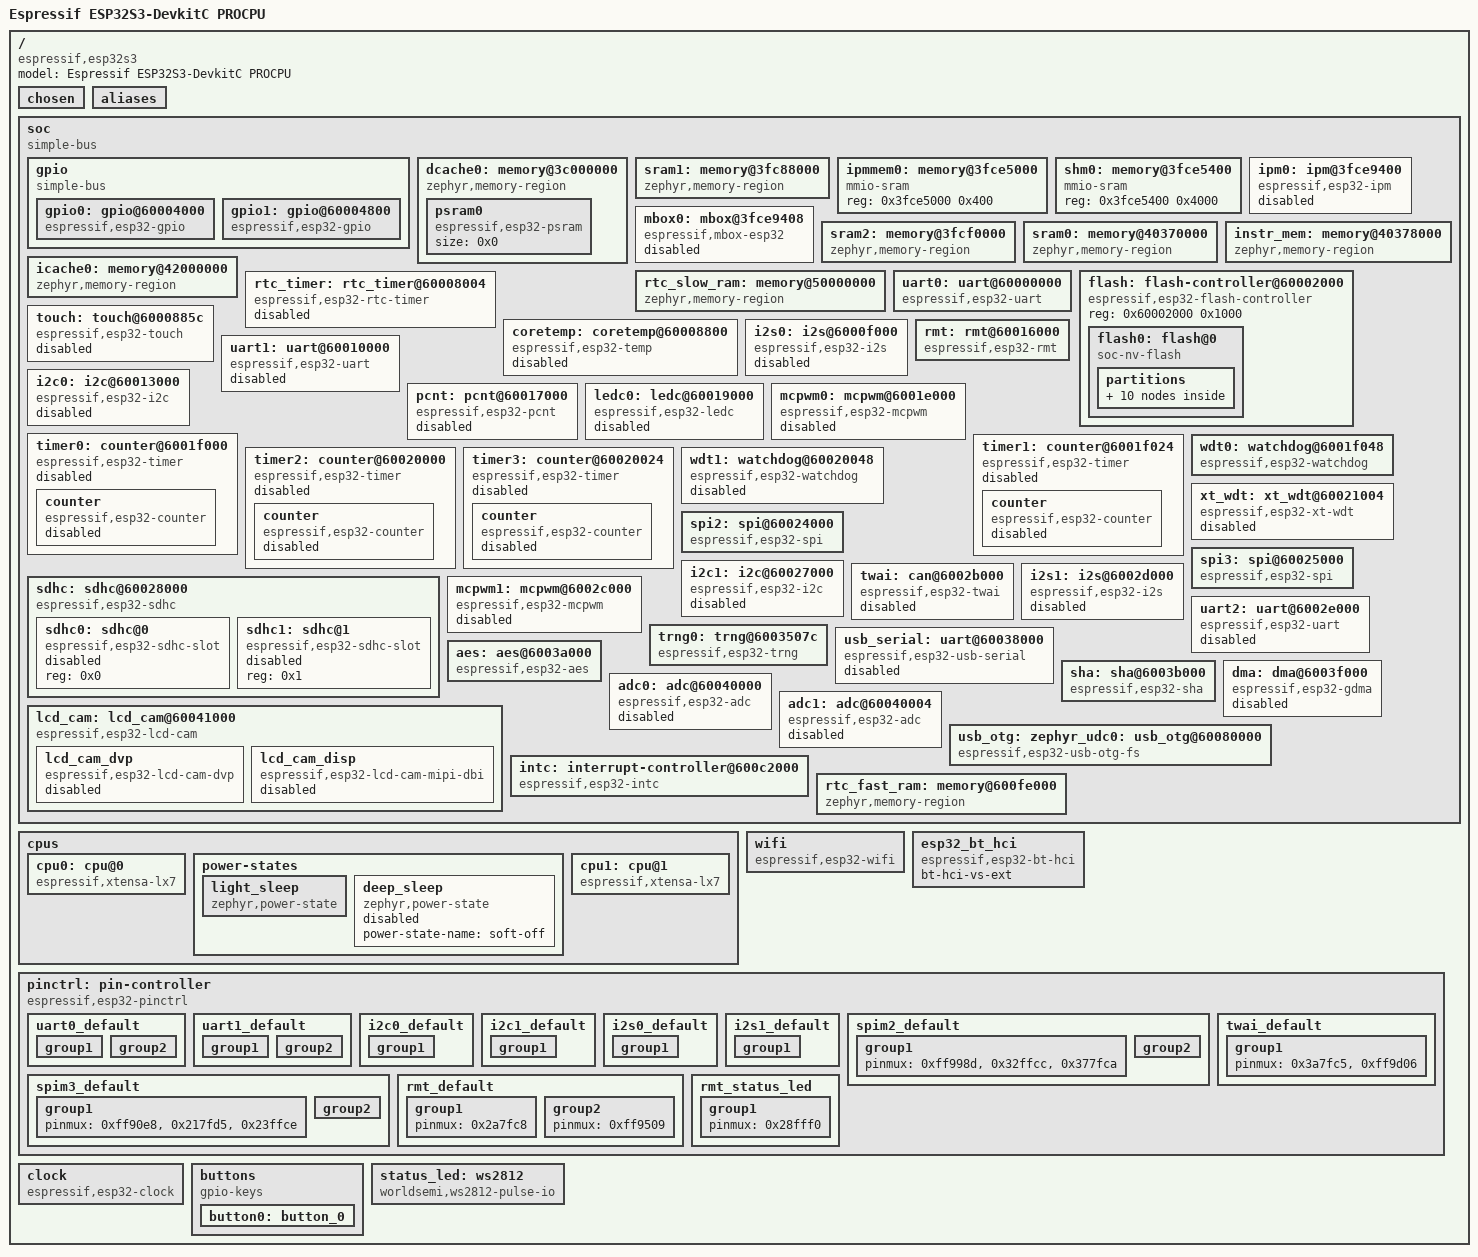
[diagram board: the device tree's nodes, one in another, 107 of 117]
/dts-v1/;

/* node '/' defined in zephyr/dts/common/skeleton.dtsi:9 */
/ {
	#address-cells = < 0x1 >;                   /* in zephyr/dts/common/skeleton.dtsi:10 */
	#size-cells = < 0x1 >;                      /* in zephyr/dts/common/skeleton.dtsi:11 */
	compatible = "espressif,esp32s3";           /* in zephyr/boards/espressif/esp32s3_devkitc/esp32s3_devkitc_procpu.dts:15 */
	model = "Espressif ESP32S3-DevkitC PROCPU"; /* in zephyr/boards/espressif/esp32s3_devkitc/esp32s3_devkitc_procpu.dts:16 */

	/* node '/chosen' defined in zephyr/dts/common/skeleton.dtsi:13 */
	chosen {
		zephyr,canbus = &twai;                    /* in zephyr/dts/xtensa/espressif/esp32s3/esp32s3_common.dtsi:22 */
		zephyr,entropy = &trng0;                  /* in zephyr/dts/xtensa/espressif/esp32s3/esp32s3_common.dtsi:23 */
		zephyr,flash-controller = &flash;         /* in zephyr/dts/xtensa/espressif/esp32s3/esp32s3_common.dtsi:24 */
		zephyr,sram = &sram1;                     /* in zephyr/boards/espressif/esp32s3_devkitc/esp32s3_devkitc_procpu.dts:26 */
		zephyr,console = &uart0;                  /* in zephyr/boards/espressif/esp32s3_devkitc/esp32s3_devkitc_procpu.dts:27 */
		zephyr,shell-uart = &uart0;               /* in zephyr/boards/espressif/esp32s3_devkitc/esp32s3_devkitc_procpu.dts:28 */
		zephyr,flash = &flash0;                   /* in zephyr/boards/espressif/esp32s3_devkitc/esp32s3_devkitc_procpu.dts:29 */
		zephyr,code-partition = &slot0_partition; /* in zephyr/boards/espressif/esp32s3_devkitc/esp32s3_devkitc_procpu.dts:30 */
		zephyr,bt-hci = &esp32_bt_hci;            /* in zephyr/boards/espressif/esp32s3_devkitc/esp32s3_devkitc_procpu.dts:31 */
	};

	/* node '/aliases' defined in zephyr/dts/common/skeleton.dtsi:15 */
	aliases {
		die-temp0 = &coretemp; /* in zephyr/dts/xtensa/espressif/esp32s3/esp32s3_common.dtsi:18 */
		i2c-0 = &i2c0;         /* in zephyr/boards/espressif/esp32s3_devkitc/esp32s3_devkitc_procpu.dts:19 */
		watchdog0 = &wdt0;     /* in zephyr/boards/espressif/esp32s3_devkitc/esp32s3_devkitc_procpu.dts:20 */
		uart-0 = &uart0;       /* in zephyr/boards/espressif/esp32s3_devkitc/esp32s3_devkitc_procpu.dts:21 */
		sw0 = &button0;        /* in zephyr/boards/espressif/esp32s3_devkitc/esp32s3_devkitc_procpu.dts:22 */
	};

	/* node '/soc' defined in zephyr/dts/xtensa/xtensa.dtsi:10 */
	soc {
		compatible = "simple-bus"; /* in zephyr/dts/xtensa/espressif/esp32s3/esp32s3_common.dtsi:97 */
		ranges;                    /* in zephyr/dts/xtensa/espressif/esp32s3/esp32s3_common.dtsi:98 */
		#address-cells = < 0x1 >;  /* in zephyr/dts/xtensa/espressif/esp32s3/esp32s3_common.dtsi:99 */
		#size-cells = < 0x1 >;     /* in zephyr/dts/xtensa/espressif/esp32s3/esp32s3_common.dtsi:100 */

		/* node '/soc/gpio' defined in zephyr/dts/xtensa/espressif/esp32s3/esp32s3_common.dtsi:102 */
		gpio: gpio {
			compatible = "simple-bus";                                     /* in zephyr/dts/xtensa/espressif/esp32s3/esp32s3_common.dtsi:103 */
			ranges;                                                        /* in zephyr/dts/xtensa/espressif/esp32s3/esp32s3_common.dtsi:104 */
			gpio-map-mask = < 0xffffffe0 0xffffffc0 >;                     /* in zephyr/dts/xtensa/espressif/esp32s3/esp32s3_common.dtsi:105 */
			gpio-map-pass-thru = < 0x1f 0x3f >;                            /* in zephyr/dts/xtensa/espressif/esp32s3/esp32s3_common.dtsi:106 */
			gpio-map = < 0x0 0x0 &gpio0 0x0 0x0 0x20 0x0 &gpio1 0x0 0x0 >; /* in zephyr/dts/xtensa/espressif/esp32s3/esp32s3_common.dtsi:107 */
			#gpio-cells = < 0x2 >;                                         /* in zephyr/dts/xtensa/espressif/esp32s3/esp32s3_common.dtsi:109 */
			#address-cells = < 0x1 >;                                      /* in zephyr/dts/xtensa/espressif/esp32s3/esp32s3_common.dtsi:110 */
			#size-cells = < 0x1 >;                                         /* in zephyr/dts/xtensa/espressif/esp32s3/esp32s3_common.dtsi:111 */

			/* node '/soc/gpio/gpio@60004000' defined in zephyr/dts/xtensa/espressif/esp32s3/esp32s3_common.dtsi:113 */
			gpio0: gpio@60004000 {
				compatible = "espressif,esp32-gpio"; /* in zephyr/dts/xtensa/espressif/esp32s3/esp32s3_common.dtsi:114 */
				reg = < 0x60004000 0x800 >;          /* in zephyr/dts/xtensa/espressif/esp32s3/esp32s3_common.dtsi:115 */
				gpio-controller;                     /* in zephyr/dts/xtensa/espressif/esp32s3/esp32s3_common.dtsi:116 */
				#gpio-cells = < 0x2 >;               /* in zephyr/dts/xtensa/espressif/esp32s3/esp32s3_common.dtsi:117 */
				interrupts = < 0x10 0x0 0x0 >;       /* in zephyr/dts/xtensa/espressif/esp32s3/esp32s3_common.dtsi:118 */
				interrupt-parent = < &intc >;        /* in zephyr/dts/xtensa/espressif/esp32s3/esp32s3_common.dtsi:119 */
				ngpios = < 0x20 >;                   /* in zephyr/dts/xtensa/espressif/esp32s3/esp32s3_common.dtsi:125 */
				status = "okay";                     /* in zephyr/boards/espressif/esp32s3_devkitc/esp32s3_devkitc_procpu.dts:62 */
				phandle = < 0x1 >;                   /* in zephyr/dts/xtensa/espressif/esp32s3/esp32s3_common.dtsi:107 */
			};

			/* node '/soc/gpio/gpio@60004800' defined in zephyr/dts/xtensa/espressif/esp32s3/esp32s3_common.dtsi:128 */
			gpio1: gpio@60004800 {
				compatible = "espressif,esp32-gpio"; /* in zephyr/dts/xtensa/espressif/esp32s3/esp32s3_common.dtsi:129 */
				reg = < 0x60004800 0x800 >;          /* in zephyr/dts/xtensa/espressif/esp32s3/esp32s3_common.dtsi:130 */
				gpio-controller;                     /* in zephyr/dts/xtensa/espressif/esp32s3/esp32s3_common.dtsi:131 */
				#gpio-cells = < 0x2 >;               /* in zephyr/dts/xtensa/espressif/esp32s3/esp32s3_common.dtsi:132 */
				interrupts = < 0x10 0x0 0x0 >;       /* in zephyr/dts/xtensa/espressif/esp32s3/esp32s3_common.dtsi:133 */
				interrupt-parent = < &intc >;        /* in zephyr/dts/xtensa/espressif/esp32s3/esp32s3_common.dtsi:134 */
				ngpios = < 0x16 >;                   /* in zephyr/dts/xtensa/espressif/esp32s3/esp32s3_common.dtsi:135 */
				status = "okay";                     /* in zephyr/boards/espressif/esp32s3_devkitc/esp32s3_devkitc_procpu.dts:66 */
				phandle = < 0x2 >;                   /* in zephyr/dts/xtensa/espressif/esp32s3/esp32s3_common.dtsi:107 */
			};
		};

		/* node '/soc/memory@3c000000' defined in zephyr/dts/xtensa/espressif/esp32s3/esp32s3_common.dtsi:139 */
		dcache0: memory@3c000000 {
			compatible = "zephyr,memory-region"; /* in zephyr/dts/xtensa/espressif/esp32s3/esp32s3_common.dtsi:140 */
			reg = < 0x3c000000 0x2000000 >;      /* in zephyr/dts/xtensa/espressif/esp32s3/esp32s3_common.dtsi:141 */
			zephyr,memory-region = "DCACHE0";    /* in zephyr/dts/xtensa/espressif/esp32s3/esp32s3_common.dtsi:142 */

			/* node '/soc/memory@3c000000/psram0' defined in zephyr/dts/xtensa/espressif/esp32s3/esp32s3_common.dtsi:144 */
			psram0: psram0 {
				compatible = "espressif,esp32-psram"; /* in zephyr/dts/xtensa/espressif/esp32s3/esp32s3_common.dtsi:145 */
				size = < 0x0 >;                       /* in zephyr/dts/xtensa/espressif/esp32s3/esp32s3_common.dtsi:146 */
			};
		};

		/* node '/soc/memory@3fc88000' defined in zephyr/dts/xtensa/espressif/esp32s3/esp32s3_common.dtsi:150 */
		sram1: memory@3fc88000 {
			compatible = "zephyr,memory-region",
			             "mmio-sram";            /* in zephyr/dts/xtensa/espressif/esp32s3/esp32s3_common.dtsi:151 */
			reg = < 0x3fc88000 0x68000 >;        /* in zephyr/dts/xtensa/espressif/esp32s3/esp32s3_common.dtsi:152 */
			zephyr,memory-region = "SRAM1";      /* in zephyr/dts/xtensa/espressif/esp32s3/esp32s3_common.dtsi:153 */
		};

		/* node '/soc/memory@3fce5000' defined in zephyr/dts/xtensa/espressif/esp32s3/esp32s3_common.dtsi:156 */
		ipmmem0: memory@3fce5000 {
			compatible = "mmio-sram";   /* in zephyr/dts/xtensa/espressif/esp32s3/esp32s3_common.dtsi:157 */
			reg = < 0x3fce5000 0x400 >; /* in zephyr/dts/xtensa/espressif/esp32s3/esp32s3_common.dtsi:158 */
			phandle = < 0x4 >;          /* in zephyr/dts/xtensa/espressif/esp32s3/esp32s3_common.dtsi:169 */
		};

		/* node '/soc/memory@3fce5400' defined in zephyr/dts/xtensa/espressif/esp32s3/esp32s3_common.dtsi:161 */
		shm0: memory@3fce5400 {
			compatible = "mmio-sram";    /* in zephyr/dts/xtensa/espressif/esp32s3/esp32s3_common.dtsi:162 */
			reg = < 0x3fce5400 0x4000 >; /* in zephyr/dts/xtensa/espressif/esp32s3/esp32s3_common.dtsi:163 */
		};

		/* node '/soc/ipm@3fce9400' defined in zephyr/dts/xtensa/espressif/esp32s3/esp32s3_common.dtsi:166 */
		ipm0: ipm@3fce9400 {
			compatible = "espressif,esp32-ipm"; /* in zephyr/dts/xtensa/espressif/esp32s3/esp32s3_common.dtsi:167 */
			reg = < 0x3fce9400 0x8 >;           /* in zephyr/dts/xtensa/espressif/esp32s3/esp32s3_common.dtsi:168 */
			shared-memory = < &ipmmem0 >;       /* in zephyr/dts/xtensa/espressif/esp32s3/esp32s3_common.dtsi:169 */
			shared-memory-size = < 0x400 >;     /* in zephyr/dts/xtensa/espressif/esp32s3/esp32s3_common.dtsi:170 */
			interrupts = < 0x4f 0x0 0x0 >,
			             < 0x50 0x0 0x0 >;      /* in zephyr/dts/xtensa/espressif/esp32s3/esp32s3_common.dtsi:171 */
			interrupt-parent = < &intc >;       /* in zephyr/dts/xtensa/espressif/esp32s3/esp32s3_common.dtsi:173 */
			status = "disabled";                /* in zephyr/dts/xtensa/espressif/esp32s3/esp32s3_common.dtsi:174 */
		};

		/* node '/soc/mbox@3fce9408' defined in zephyr/dts/xtensa/espressif/esp32s3/esp32s3_common.dtsi:177 */
		mbox0: mbox@3fce9408 {
			compatible = "espressif,mbox-esp32"; /* in zephyr/dts/xtensa/espressif/esp32s3/esp32s3_common.dtsi:178 */
			reg = < 0x3fce9408 0x8 >;            /* in zephyr/dts/xtensa/espressif/esp32s3/esp32s3_common.dtsi:179 */
			shared-memory = < &ipmmem0 >;        /* in zephyr/dts/xtensa/espressif/esp32s3/esp32s3_common.dtsi:180 */
			shared-memory-size = < 0x400 >;      /* in zephyr/dts/xtensa/espressif/esp32s3/esp32s3_common.dtsi:181 */
			interrupts = < 0x4f 0x0 0x0 >,
			             < 0x50 0x0 0x0 >;       /* in zephyr/dts/xtensa/espressif/esp32s3/esp32s3_common.dtsi:182 */
			interrupt-parent = < &intc >;        /* in zephyr/dts/xtensa/espressif/esp32s3/esp32s3_common.dtsi:184 */
			#mbox-cells = < 0x1 >;               /* in zephyr/dts/xtensa/espressif/esp32s3/esp32s3_common.dtsi:185 */
			status = "disabled";                 /* in zephyr/dts/xtensa/espressif/esp32s3/esp32s3_common.dtsi:186 */
		};

		/* node '/soc/memory@3fcf0000' defined in zephyr/dts/xtensa/espressif/esp32s3/esp32s3_common.dtsi:189 */
		sram2: memory@3fcf0000 {
			compatible = "zephyr,memory-region",
			             "mmio-sram";            /* in zephyr/dts/xtensa/espressif/esp32s3/esp32s3_common.dtsi:190 */
			reg = < 0x3fcf0000 0x10000 >;        /* in zephyr/dts/xtensa/espressif/esp32s3/esp32s3_common.dtsi:191 */
			zephyr,memory-region = "SRAM2";      /* in zephyr/dts/xtensa/espressif/esp32s3/esp32s3_common.dtsi:192 */
		};

		/* node '/soc/memory@40370000' defined in zephyr/dts/xtensa/espressif/esp32s3/esp32s3_common.dtsi:195 */
		sram0: memory@40370000 {
			compatible = "zephyr,memory-region",
			             "mmio-sram";            /* in zephyr/dts/xtensa/espressif/esp32s3/esp32s3_common.dtsi:196 */
			reg = < 0x40370000 0x8000 >;         /* in zephyr/dts/xtensa/espressif/esp32s3/esp32s3_common.dtsi:197 */
			zephyr,memory-region = "SRAM0";      /* in zephyr/dts/xtensa/espressif/esp32s3/esp32s3_common.dtsi:198 */
		};

		/* node '/soc/memory@40378000' defined in zephyr/dts/xtensa/espressif/esp32s3/esp32s3_common.dtsi:201 */
		instr_mem: memory@40378000 {
			compatible = "zephyr,memory-region"; /* in zephyr/dts/xtensa/espressif/esp32s3/esp32s3_common.dtsi:202 */
			reg = < 0x40378000 0x68000 >;        /* in zephyr/dts/xtensa/espressif/esp32s3/esp32s3_common.dtsi:203 */
			zephyr,memory-region = "IRAM";       /* in zephyr/dts/xtensa/espressif/esp32s3/esp32s3_common.dtsi:204 */
		};

		/* node '/soc/memory@42000000' defined in zephyr/dts/xtensa/espressif/esp32s3/esp32s3_common.dtsi:207 */
		icache0: memory@42000000 {
			compatible = "zephyr,memory-region"; /* in zephyr/dts/xtensa/espressif/esp32s3/esp32s3_common.dtsi:208 */
			reg = < 0x42000000 0x2000000 >;      /* in zephyr/dts/xtensa/espressif/esp32s3/esp32s3_common.dtsi:209 */
			zephyr,memory-region = "ICACHE0";    /* in zephyr/dts/xtensa/espressif/esp32s3/esp32s3_common.dtsi:210 */
		};

		/* node '/soc/memory@50000000' defined in zephyr/dts/xtensa/espressif/esp32s3/esp32s3_common.dtsi:213 */
		rtc_slow_ram: memory@50000000 {
			compatible = "zephyr,memory-region",
			             "mmio-sram";              /* in zephyr/dts/xtensa/espressif/esp32s3/esp32s3_common.dtsi:214 */
			reg = < 0x50000000 0x2000 >;           /* in zephyr/dts/xtensa/espressif/esp32s3/esp32s3_common.dtsi:215 */
			zephyr,memory-region = "RTC_SLOW_RAM"; /* in zephyr/dts/xtensa/espressif/esp32s3/esp32s3_common.dtsi:216 */
		};

		/* node '/soc/uart@60000000' defined in zephyr/dts/xtensa/espressif/esp32s3/esp32s3_common.dtsi:219 */
		uart0: uart@60000000 {
			compatible = "espressif,esp32-uart"; /* in zephyr/dts/xtensa/espressif/esp32s3/esp32s3_common.dtsi:220 */
			reg = < 0x60000000 0x1000 >;         /* in zephyr/dts/xtensa/espressif/esp32s3/esp32s3_common.dtsi:221 */
			interrupts = < 0x1b 0x0 0x0 >;       /* in zephyr/dts/xtensa/espressif/esp32s3/esp32s3_common.dtsi:222 */
			interrupt-parent = < &intc >;        /* in zephyr/dts/xtensa/espressif/esp32s3/esp32s3_common.dtsi:223 */
			clocks = < &clock 0x65 >;            /* in zephyr/dts/xtensa/espressif/esp32s3/esp32s3_common.dtsi:224 */
			current-speed = < 0x1c200 >;         /* in zephyr/boards/espressif/esp32s3_devkitc/esp32s3_devkitc_procpu.dts:55 */
			pinctrl-0 = < &uart0_default >;      /* in zephyr/boards/espressif/esp32s3_devkitc/esp32s3_devkitc_procpu.dts:56 */
			pinctrl-names = "default";           /* in zephyr/boards/espressif/esp32s3_devkitc/esp32s3_devkitc_procpu.dts:57 */
			status = "okay";                     /* in zephyr/boards/espressif/esp32s3_devkitc/esp32s3_devkitc_procpu.dts:58 */
		};

		/* node '/soc/flash-controller@60002000' defined in zephyr/dts/xtensa/espressif/esp32s3/esp32s3_common.dtsi:228 */
		flash: flash-controller@60002000 {
			compatible = "espressif,esp32-flash-controller"; /* in zephyr/dts/xtensa/espressif/esp32s3/esp32s3_common.dtsi:229 */
			reg = < 0x60002000 0x1000 >;                     /* in zephyr/dts/xtensa/espressif/esp32s3/esp32s3_common.dtsi:230 */
			ranges;                                          /* in zephyr/dts/xtensa/espressif/esp32s3/esp32s3_common.dtsi:231 */
			#address-cells = < 0x1 >;                        /* in zephyr/dts/xtensa/espressif/esp32s3/esp32s3_common.dtsi:232 */
			#size-cells = < 0x1 >;                           /* in zephyr/dts/xtensa/espressif/esp32s3/esp32s3_common.dtsi:233 */

			/* node '/soc/flash-controller@60002000/flash@0' defined in zephyr/dts/xtensa/espressif/esp32s3/esp32s3_common.dtsi:235 */
			flash0: flash@0 {
				compatible = "soc-nv-flash";   /* in zephyr/dts/xtensa/espressif/esp32s3/esp32s3_common.dtsi:236 */
				erase-block-size = < 0x1000 >; /* in zephyr/dts/xtensa/espressif/esp32s3/esp32s3_common.dtsi:237 */
				write-block-size = < 0x4 >;    /* in zephyr/dts/xtensa/espressif/esp32s3/esp32s3_common.dtsi:238 */
				#address-cells = < 0x1 >;      /* in zephyr/dts/xtensa/espressif/esp32s3/esp32s3_common.dtsi:239 */
				#size-cells = < 0x1 >;         /* in zephyr/dts/xtensa/espressif/esp32s3/esp32s3_common.dtsi:240 */
				reg = < 0x0 0x800000 >;        /* in zephyr/boards/espressif/esp32s3_devkitc/esp32s3_devkitc_procpu.dts:46 */
				ranges = < 0x0 0x0 0x800000 >; /* in zephyr/boards/espressif/esp32s3_devkitc/esp32s3_devkitc_procpu.dts:47 */

				/* node '/soc/flash-controller@60002000/flash@0/partitions' defined in zephyr/dts/vendor/espressif/partitions_0x0_amp_4M.dtsi:8 */
				partitions {
					ranges;                   /* in zephyr/dts/vendor/espressif/partitions_0x0_amp_4M.dtsi:9 */
					#address-cells = < 0x1 >; /* in zephyr/dts/vendor/espressif/partitions_0x0_amp_4M.dtsi:10 */
					#size-cells = < 0x1 >;    /* in zephyr/dts/vendor/espressif/partitions_0x0_amp_4M.dtsi:11 */

					/* node '/soc/flash-controller@60002000/flash@0/partitions/partition@0' defined in zephyr/dts/vendor/espressif/partitions_0x0_amp_4M.dtsi:13 */
					boot_partition: partition@0 {
						compatible = "zephyr,mapped-partition"; /* in zephyr/dts/vendor/espressif/partitions_0x0_amp_4M.dtsi:14 */
						reg = < 0x0 0x10000 >;                  /* in zephyr/dts/vendor/espressif/partitions_0x0_amp_4M.dtsi:15 */
						label = "mcuboot";                      /* in zephyr/dts/vendor/espressif/partitions_0x0_amp_4M.dtsi:16 */
					};

					/* node '/soc/flash-controller@60002000/flash@0/partitions/partition@10000' defined in zephyr/dts/vendor/espressif/partitions_0x0_amp_4M.dtsi:19 */
					sys_partition: partition@10000 {
						compatible = "zephyr,mapped-partition"; /* in zephyr/dts/vendor/espressif/partitions_0x0_amp_4M.dtsi:20 */
						reg = < 0x10000 0x10000 >;              /* in zephyr/dts/vendor/espressif/partitions_0x0_amp_4M.dtsi:21 */
						label = "sys";                          /* in zephyr/dts/vendor/espressif/partitions_0x0_amp_4M.dtsi:22 */
					};

					/* node '/soc/flash-controller@60002000/flash@0/partitions/partition@20000' defined in zephyr/dts/vendor/espressif/partitions_0x0_amp_4M.dtsi:25 */
					slot0_partition: partition@20000 {
						compatible = "zephyr,mapped-partition"; /* in zephyr/dts/vendor/espressif/partitions_0x0_amp_4M.dtsi:26 */
						reg = < 0x20000 0x150000 >;             /* in zephyr/dts/vendor/espressif/partitions_0x0_amp_4M.dtsi:27 */
						label = "image-0";                      /* in zephyr/dts/vendor/espressif/partitions_0x0_amp_4M.dtsi:28 */
					};

					/* node '/soc/flash-controller@60002000/flash@0/partitions/partition@170000' defined in zephyr/dts/vendor/espressif/partitions_0x0_amp_4M.dtsi:31 */
					slot1_partition: partition@170000 {
						compatible = "zephyr,mapped-partition"; /* in zephyr/dts/vendor/espressif/partitions_0x0_amp_4M.dtsi:32 */
						reg = < 0x170000 0x150000 >;            /* in zephyr/dts/vendor/espressif/partitions_0x0_amp_4M.dtsi:33 */
						label = "image-1";                      /* in zephyr/dts/vendor/espressif/partitions_0x0_amp_4M.dtsi:34 */
					};

					/* node '/soc/flash-controller@60002000/flash@0/partitions/partition@2c0000' defined in zephyr/dts/vendor/espressif/partitions_0x0_amp_4M.dtsi:37 */
					slot0_appcpu_partition: partition@2c0000 {
						compatible = "zephyr,mapped-partition"; /* in zephyr/dts/vendor/espressif/partitions_0x0_amp_4M.dtsi:38 */
						reg = < 0x2c0000 0x70000 >;             /* in zephyr/dts/vendor/espressif/partitions_0x0_amp_4M.dtsi:39 */
						label = "image-0-appcpu";               /* in zephyr/dts/vendor/espressif/partitions_0x0_amp_4M.dtsi:40 */
					};

					/* node '/soc/flash-controller@60002000/flash@0/partitions/partition@330000' defined in zephyr/dts/vendor/espressif/partitions_0x0_amp_4M.dtsi:43 */
					slot1_appcpu_partition: partition@330000 {
						compatible = "zephyr,mapped-partition"; /* in zephyr/dts/vendor/espressif/partitions_0x0_amp_4M.dtsi:44 */
						reg = < 0x330000 0x70000 >;             /* in zephyr/dts/vendor/espressif/partitions_0x0_amp_4M.dtsi:45 */
						label = "image-1-appcpu";               /* in zephyr/dts/vendor/espressif/partitions_0x0_amp_4M.dtsi:46 */
					};

					/* node '/soc/flash-controller@60002000/flash@0/partitions/partition@3a0000' defined in zephyr/dts/vendor/espressif/partitions_0x0_amp_4M.dtsi:49 */
					slot0_lpcore_partition: partition@3a0000 {
						compatible = "zephyr,mapped-partition"; /* in zephyr/dts/vendor/espressif/partitions_0x0_amp_4M.dtsi:50 */
						reg = < 0x3a0000 0x8000 >;              /* in zephyr/dts/vendor/espressif/partitions_0x0_amp_4M.dtsi:51 */
						label = "image-0-lpcore";               /* in zephyr/dts/vendor/espressif/partitions_0x0_amp_4M.dtsi:52 */
					};

					/* node '/soc/flash-controller@60002000/flash@0/partitions/partition@3a8000' defined in zephyr/dts/vendor/espressif/partitions_0x0_amp_4M.dtsi:55 */
					slot1_lpcore_partition: partition@3a8000 {
						compatible = "zephyr,mapped-partition"; /* in zephyr/dts/vendor/espressif/partitions_0x0_amp_4M.dtsi:56 */
						reg = < 0x3a8000 0x8000 >;              /* in zephyr/dts/vendor/espressif/partitions_0x0_amp_4M.dtsi:57 */
						label = "image-1-lpcore";               /* in zephyr/dts/vendor/espressif/partitions_0x0_amp_4M.dtsi:58 */
					};

					/* node '/soc/flash-controller@60002000/flash@0/partitions/partition@3b0000' defined in zephyr/dts/vendor/espressif/partitions_0x0_amp_4M.dtsi:61 */
					storage_partition: partition@3b0000 {
						compatible = "zephyr,mapped-partition"; /* in zephyr/dts/vendor/espressif/partitions_0x0_amp_4M.dtsi:62 */
						reg = < 0x3b0000 0x30000 >;             /* in zephyr/dts/vendor/espressif/partitions_0x0_amp_4M.dtsi:63 */
						label = "storage";                      /* in zephyr/dts/vendor/espressif/partitions_0x0_amp_4M.dtsi:64 */
					};

					/* node '/soc/flash-controller@60002000/flash@0/partitions/partition@3ff000' defined in zephyr/dts/vendor/espressif/partitions_0x0_amp_4M.dtsi:67 */
					coredump_partition: partition@3ff000 {
						compatible = "zephyr,mapped-partition"; /* in zephyr/dts/vendor/espressif/partitions_0x0_amp_4M.dtsi:68 */
						reg = < 0x3ff000 0x1000 >;              /* in zephyr/dts/vendor/espressif/partitions_0x0_amp_4M.dtsi:69 */
						label = "coredump";                     /* in zephyr/dts/vendor/espressif/partitions_0x0_amp_4M.dtsi:70 */
					};
				};
			};
		};

		/* node '/soc/rtc_timer@60008004' defined in zephyr/dts/xtensa/espressif/esp32s3/esp32s3_common.dtsi:245 */
		rtc_timer: rtc_timer@60008004 {
			compatible = "espressif,esp32-rtc-timer"; /* in zephyr/dts/xtensa/espressif/esp32s3/esp32s3_common.dtsi:246 */
			reg = < 0x60008004 0xc >;                 /* in zephyr/dts/xtensa/espressif/esp32s3/esp32s3_common.dtsi:247 */
			clocks = < &clock 0xc >;                  /* in zephyr/dts/xtensa/espressif/esp32s3/esp32s3_common.dtsi:248 */
			interrupts = < 0x27 0x0 0x0 >;            /* in zephyr/dts/xtensa/espressif/esp32s3/esp32s3_common.dtsi:249 */
			interrupt-parent = < &intc >;             /* in zephyr/dts/xtensa/espressif/esp32s3/esp32s3_common.dtsi:250 */
			status = "disabled";                      /* in zephyr/dts/xtensa/espressif/esp32s3/esp32s3_common.dtsi:251 */
		};

		/* node '/soc/coretemp@60008800' defined in zephyr/dts/xtensa/espressif/esp32s3/esp32s3_common.dtsi:254 */
		coretemp: coretemp@60008800 {
			compatible = "espressif,esp32-temp"; /* in zephyr/dts/xtensa/espressif/esp32s3/esp32s3_common.dtsi:255 */
			reg = < 0x60008800 0x4 >;            /* in zephyr/dts/xtensa/espressif/esp32s3/esp32s3_common.dtsi:256 */
			friendly-name = "coretemp";          /* in zephyr/dts/xtensa/espressif/esp32s3/esp32s3_common.dtsi:257 */
			status = "disabled";                 /* in zephyr/dts/xtensa/espressif/esp32s3/esp32s3_common.dtsi:258 */
		};

		/* node '/soc/touch@6000885c' defined in zephyr/dts/xtensa/espressif/esp32s3/esp32s3_common.dtsi:261 */
		touch: touch@6000885c {
			compatible = "espressif,esp32-touch";      /* in zephyr/dts/xtensa/espressif/esp32s3/esp32s3_common.dtsi:262 */
			reg = < 0x6000885c 0x88 0x60008908 0x18 >; /* in zephyr/dts/xtensa/espressif/esp32s3/esp32s3_common.dtsi:263 */
			interrupts = < 0x27 0x0 0x0 >;             /* in zephyr/dts/xtensa/espressif/esp32s3/esp32s3_common.dtsi:264 */
			interrupt-parent = < &intc >;              /* in zephyr/dts/xtensa/espressif/esp32s3/esp32s3_common.dtsi:265 */
			status = "disabled";                       /* in zephyr/dts/xtensa/espressif/esp32s3/esp32s3_common.dtsi:266 */
			debounce-interval-ms = < 0x1e >;           /* in zephyr/boards/espressif/esp32s3_devkitc/esp32s3_devkitc_procpu.dts:70 */
			href-microvolt = < 0x2932e0 >;             /* in zephyr/boards/espressif/esp32s3_devkitc/esp32s3_devkitc_procpu.dts:71 */
			lref-microvolt = < 0x7a120 >;              /* in zephyr/boards/espressif/esp32s3_devkitc/esp32s3_devkitc_procpu.dts:72 */
			href-atten-microvolt = < 0xf4240 >;        /* in zephyr/boards/espressif/esp32s3_devkitc/esp32s3_devkitc_procpu.dts:73 */
			filter-mode = < 0x2 >;                     /* in zephyr/boards/espressif/esp32s3_devkitc/esp32s3_devkitc_procpu.dts:74 */
			filter-debounce-cnt = < 0x1 >;             /* in zephyr/boards/espressif/esp32s3_devkitc/esp32s3_devkitc_procpu.dts:75 */
			filter-noise-thr = < 0x0 >;                /* in zephyr/boards/espressif/esp32s3_devkitc/esp32s3_devkitc_procpu.dts:76 */
			filter-jitter-step = < 0x4 >;              /* in zephyr/boards/espressif/esp32s3_devkitc/esp32s3_devkitc_procpu.dts:77 */
			filter-smooth-level = < 0x1 >;             /* in zephyr/boards/espressif/esp32s3_devkitc/esp32s3_devkitc_procpu.dts:78 */
		};

		/* node '/soc/i2s@6000f000' defined in zephyr/dts/xtensa/espressif/esp32s3/esp32s3_common.dtsi:269 */
		i2s0: i2s@6000f000 {
			compatible = "espressif,esp32-i2s"; /* in zephyr/dts/xtensa/espressif/esp32s3/esp32s3_common.dtsi:270 */
			reg = < 0x6000f000 0x1000 >;        /* in zephyr/dts/xtensa/espressif/esp32s3/esp32s3_common.dtsi:271 */
			#address-cells = < 0x1 >;           /* in zephyr/dts/xtensa/espressif/esp32s3/esp32s3_common.dtsi:272 */
			#size-cells = < 0x0 >;              /* in zephyr/dts/xtensa/espressif/esp32s3/esp32s3_common.dtsi:273 */
			interrupts = < 0x19 0x0 0x0 >;      /* in zephyr/dts/xtensa/espressif/esp32s3/esp32s3_common.dtsi:274 */
			interrupt-parent = < &intc >;       /* in zephyr/dts/xtensa/espressif/esp32s3/esp32s3_common.dtsi:275 */
			clocks = < &clock 0x69 >;           /* in zephyr/dts/xtensa/espressif/esp32s3/esp32s3_common.dtsi:276 */
			dmas = < &dma 0x2 >,
			       < &dma 0x3 >;                /* in zephyr/dts/xtensa/espressif/esp32s3/esp32s3_common.dtsi:277 */
			dma-names = "rx",
			            "tx";                   /* in zephyr/dts/xtensa/espressif/esp32s3/esp32s3_common.dtsi:278 */
			unit = < 0x0 >;                     /* in zephyr/dts/xtensa/espressif/esp32s3/esp32s3_common.dtsi:279 */
			status = "disabled";                /* in zephyr/dts/xtensa/espressif/esp32s3/esp32s3_common.dtsi:280 */
			pinctrl-0 = < &i2s0_default >;      /* in zephyr/boards/espressif/esp32s3_devkitc/esp32s3_devkitc_procpu.dts:94 */
			pinctrl-names = "default";          /* in zephyr/boards/espressif/esp32s3_devkitc/esp32s3_devkitc_procpu.dts:95 */
		};

		/* node '/soc/uart@60010000' defined in zephyr/dts/xtensa/espressif/esp32s3/esp32s3_common.dtsi:283 */
		uart1: uart@60010000 {
			compatible = "espressif,esp32-uart"; /* in zephyr/dts/xtensa/espressif/esp32s3/esp32s3_common.dtsi:284 */
			reg = < 0x60010000 0x1000 >;         /* in zephyr/dts/xtensa/espressif/esp32s3/esp32s3_common.dtsi:285 */
			interrupts = < 0x1c 0x0 0x0 >;       /* in zephyr/dts/xtensa/espressif/esp32s3/esp32s3_common.dtsi:286 */
			interrupt-parent = < &intc >;        /* in zephyr/dts/xtensa/espressif/esp32s3/esp32s3_common.dtsi:287 */
			clocks = < &clock 0x0 >;             /* in zephyr/dts/xtensa/espressif/esp32s3/esp32s3_common.dtsi:288 */
			status = "disabled";                 /* in zephyr/dts/xtensa/espressif/esp32s3/esp32s3_common.dtsi:289 */
		};

		/* node '/soc/i2c@60013000' defined in zephyr/dts/xtensa/espressif/esp32s3/esp32s3_common.dtsi:292 */
		i2c0: i2c@60013000 {
			compatible = "espressif,esp32-i2c"; /* in zephyr/dts/xtensa/espressif/esp32s3/esp32s3_common.dtsi:293 */
			reg = < 0x60013000 0x1000 >;        /* in zephyr/dts/xtensa/espressif/esp32s3/esp32s3_common.dtsi:294 */
			#address-cells = < 0x1 >;           /* in zephyr/dts/xtensa/espressif/esp32s3/esp32s3_common.dtsi:295 */
			#size-cells = < 0x0 >;              /* in zephyr/dts/xtensa/espressif/esp32s3/esp32s3_common.dtsi:296 */
			interrupts = < 0x2a 0x0 0x0 >;      /* in zephyr/dts/xtensa/espressif/esp32s3/esp32s3_common.dtsi:297 */
			interrupt-parent = < &intc >;       /* in zephyr/dts/xtensa/espressif/esp32s3/esp32s3_common.dtsi:298 */
			clocks = < &clock 0x67 >;           /* in zephyr/dts/xtensa/espressif/esp32s3/esp32s3_common.dtsi:299 */
			status = "disabled";                /* in zephyr/dts/xtensa/espressif/esp32s3/esp32s3_common.dtsi:300 */
			clock-frequency = < 0x186a0 >;      /* in zephyr/boards/espressif/esp32s3_devkitc/esp32s3_devkitc_procpu.dts:82 */
			pinctrl-0 = < &i2c0_default >;      /* in zephyr/boards/espressif/esp32s3_devkitc/esp32s3_devkitc_procpu.dts:83 */
			pinctrl-names = "default";          /* in zephyr/boards/espressif/esp32s3_devkitc/esp32s3_devkitc_procpu.dts:84 */
		};

		/* node '/soc/rmt@60016000' defined in zephyr/dts/xtensa/espressif/esp32s3/esp32s3_common.dtsi:303 */
		rmt: rmt@60016000 {
			compatible = "espressif,esp32-rmt"; /* in zephyr/dts/xtensa/espressif/esp32s3/esp32s3_common.dtsi:304 */
			reg = < 0x60016000 0x1000 >;        /* in zephyr/dts/xtensa/espressif/esp32s3/esp32s3_common.dtsi:305 */
			#pulse-io-cells = < 0x1 >;          /* in zephyr/dts/xtensa/espressif/esp32s3/esp32s3_common.dtsi:306 */
			interrupts = < 0x28 0x0 0x0 >;      /* in zephyr/dts/xtensa/espressif/esp32s3/esp32s3_common.dtsi:307 */
			interrupt-parent = < &intc >;       /* in zephyr/dts/xtensa/espressif/esp32s3/esp32s3_common.dtsi:308 */
			clocks = < &clock 0x70 >;           /* in zephyr/dts/xtensa/espressif/esp32s3/esp32s3_common.dtsi:309 */
			pinctrl-0 = < &rmt_status_led >;    /* in ../introduction-to-rtos/task-scheduling/esp32s3_devkitc_procpu.overlay:24 */
			pinctrl-names = "default";          /* in ../introduction-to-rtos/task-scheduling/esp32s3_devkitc_procpu.overlay:25 */
			status = "okay";                    /* in ../introduction-to-rtos/task-scheduling/esp32s3_devkitc_procpu.overlay:26 */
			phandle = < 0x12 >;                 /* in ../introduction-to-rtos/task-scheduling/esp32s3_devkitc_procpu.overlay:6 */
		};

		/* node '/soc/pcnt@60017000' defined in zephyr/dts/xtensa/espressif/esp32s3/esp32s3_common.dtsi:313 */
		pcnt: pcnt@60017000 {
			compatible = "espressif,esp32-pcnt"; /* in zephyr/dts/xtensa/espressif/esp32s3/esp32s3_common.dtsi:314 */
			reg = < 0x60017000 0x1000 >;         /* in zephyr/dts/xtensa/espressif/esp32s3/esp32s3_common.dtsi:315 */
			interrupts = < 0x29 0x0 0x0 >;       /* in zephyr/dts/xtensa/espressif/esp32s3/esp32s3_common.dtsi:316 */
			interrupt-parent = < &intc >;        /* in zephyr/dts/xtensa/espressif/esp32s3/esp32s3_common.dtsi:317 */
			clocks = < &clock 0x71 >;            /* in zephyr/dts/xtensa/espressif/esp32s3/esp32s3_common.dtsi:318 */
			status = "disabled";                 /* in zephyr/dts/xtensa/espressif/esp32s3/esp32s3_common.dtsi:319 */
		};

		/* node '/soc/ledc@60019000' defined in zephyr/dts/xtensa/espressif/esp32s3/esp32s3_common.dtsi:322 */
		ledc0: ledc@60019000 {
			compatible = "espressif,esp32-ledc"; /* in zephyr/dts/xtensa/espressif/esp32s3/esp32s3_common.dtsi:323 */
			reg = < 0x60019000 0x1000 >;         /* in zephyr/dts/xtensa/espressif/esp32s3/esp32s3_common.dtsi:324 */
			#pwm-cells = < 0x3 >;                /* in zephyr/dts/xtensa/espressif/esp32s3/esp32s3_common.dtsi:325 */
			clocks = < &clock 0x64 >;            /* in zephyr/dts/xtensa/espressif/esp32s3/esp32s3_common.dtsi:326 */
			status = "disabled";                 /* in zephyr/dts/xtensa/espressif/esp32s3/esp32s3_common.dtsi:327 */
		};

		/* node '/soc/mcpwm@6001e000' defined in zephyr/dts/xtensa/espressif/esp32s3/esp32s3_common.dtsi:330 */
		mcpwm0: mcpwm@6001e000 {
			compatible = "espressif,esp32-mcpwm"; /* in zephyr/dts/xtensa/espressif/esp32s3/esp32s3_common.dtsi:331 */
			reg = < 0x6001e000 0x1000 >;          /* in zephyr/dts/xtensa/espressif/esp32s3/esp32s3_common.dtsi:332 */
			interrupts = < 0x1f 0x0 0x0 >;        /* in zephyr/dts/xtensa/espressif/esp32s3/esp32s3_common.dtsi:333 */
			interrupt-parent = < &intc >;         /* in zephyr/dts/xtensa/espressif/esp32s3/esp32s3_common.dtsi:334 */
			clocks = < &clock 0x6b >;             /* in zephyr/dts/xtensa/espressif/esp32s3/esp32s3_common.dtsi:335 */
			#pwm-cells = < 0x3 >;                 /* in zephyr/dts/xtensa/espressif/esp32s3/esp32s3_common.dtsi:336 */
			status = "disabled";                  /* in zephyr/dts/xtensa/espressif/esp32s3/esp32s3_common.dtsi:337 */
		};

		/* node '/soc/counter@6001f000' defined in zephyr/dts/xtensa/espressif/esp32s3/esp32s3_common.dtsi:340 */
		timer0: counter@6001f000 {
			compatible = "espressif,esp32-timer"; /* in zephyr/dts/xtensa/espressif/esp32s3/esp32s3_common.dtsi:341 */
			reg = < 0x6001f000 0x1000 >;          /* in zephyr/dts/xtensa/espressif/esp32s3/esp32s3_common.dtsi:342 */
			clocks = < &clock 0x3 >;              /* in zephyr/dts/xtensa/espressif/esp32s3/esp32s3_common.dtsi:343 */
			group = < 0x0 >;                      /* in zephyr/dts/xtensa/espressif/esp32s3/esp32s3_common.dtsi:344 */
			index = < 0x0 >;                      /* in zephyr/dts/xtensa/espressif/esp32s3/esp32s3_common.dtsi:345 */
			interrupts = < 0x32 0x0 0x0 >;        /* in zephyr/dts/xtensa/espressif/esp32s3/esp32s3_common.dtsi:346 */
			interrupt-parent = < &intc >;         /* in zephyr/dts/xtensa/espressif/esp32s3/esp32s3_common.dtsi:347 */
			status = "disabled";                  /* in zephyr/boards/espressif/esp32s3_devkitc/esp32s3_devkitc_procpu.dts:125 */

			/* node '/soc/counter@6001f000/counter' defined in zephyr/dts/xtensa/espressif/esp32s3/esp32s3_common.dtsi:350 */
			counter {
				compatible = "espressif,esp32-counter"; /* in zephyr/dts/xtensa/espressif/esp32s3/esp32s3_common.dtsi:351 */
				status = "disabled";                    /* in zephyr/dts/xtensa/espressif/esp32s3/esp32s3_common.dtsi:352 */
			};
		};

		/* node '/soc/counter@6001f024' defined in zephyr/dts/xtensa/espressif/esp32s3/esp32s3_common.dtsi:356 */
		timer1: counter@6001f024 {
			compatible = "espressif,esp32-timer"; /* in zephyr/dts/xtensa/espressif/esp32s3/esp32s3_common.dtsi:357 */
			reg = < 0x6001f024 0x1000 >;          /* in zephyr/dts/xtensa/espressif/esp32s3/esp32s3_common.dtsi:358 */
			clocks = < &clock 0x3 >;              /* in zephyr/dts/xtensa/espressif/esp32s3/esp32s3_common.dtsi:359 */
			group = < 0x0 >;                      /* in zephyr/dts/xtensa/espressif/esp32s3/esp32s3_common.dtsi:360 */
			index = < 0x1 >;                      /* in zephyr/dts/xtensa/espressif/esp32s3/esp32s3_common.dtsi:361 */
			interrupts = < 0x33 0x0 0x0 >;        /* in zephyr/dts/xtensa/espressif/esp32s3/esp32s3_common.dtsi:362 */
			interrupt-parent = < &intc >;         /* in zephyr/dts/xtensa/espressif/esp32s3/esp32s3_common.dtsi:363 */
			status = "disabled";                  /* in zephyr/boards/espressif/esp32s3_devkitc/esp32s3_devkitc_procpu.dts:129 */

			/* node '/soc/counter@6001f024/counter' defined in zephyr/dts/xtensa/espressif/esp32s3/esp32s3_common.dtsi:366 */
			counter {
				compatible = "espressif,esp32-counter"; /* in zephyr/dts/xtensa/espressif/esp32s3/esp32s3_common.dtsi:367 */
				status = "disabled";                    /* in zephyr/dts/xtensa/espressif/esp32s3/esp32s3_common.dtsi:368 */
			};
		};

		/* node '/soc/watchdog@6001f048' defined in zephyr/dts/xtensa/espressif/esp32s3/esp32s3_common.dtsi:372 */
		wdt0: watchdog@6001f048 {
			compatible = "espressif,esp32-watchdog"; /* in zephyr/dts/xtensa/espressif/esp32s3/esp32s3_common.dtsi:373 */
			reg = < 0x6001f048 0x20 >;               /* in zephyr/dts/xtensa/espressif/esp32s3/esp32s3_common.dtsi:374 */
			interrupts = < 0x34 0x0 0x0 >;           /* in zephyr/dts/xtensa/espressif/esp32s3/esp32s3_common.dtsi:375 */
			interrupt-parent = < &intc >;            /* in zephyr/dts/xtensa/espressif/esp32s3/esp32s3_common.dtsi:376 */
			clocks = < &clock 0x3 >;                 /* in zephyr/dts/xtensa/espressif/esp32s3/esp32s3_common.dtsi:377 */
			status = "okay";                         /* in zephyr/boards/espressif/esp32s3_devkitc/esp32s3_devkitc_procpu.dts:141 */
		};

		/* node '/soc/counter@60020000' defined in zephyr/dts/xtensa/espressif/esp32s3/esp32s3_common.dtsi:381 */
		timer2: counter@60020000 {
			compatible = "espressif,esp32-timer"; /* in zephyr/dts/xtensa/espressif/esp32s3/esp32s3_common.dtsi:382 */
			reg = < 0x60020000 0x1000 >;          /* in zephyr/dts/xtensa/espressif/esp32s3/esp32s3_common.dtsi:383 */
			clocks = < &clock 0x4 >;              /* in zephyr/dts/xtensa/espressif/esp32s3/esp32s3_common.dtsi:384 */
			group = < 0x1 >;                      /* in zephyr/dts/xtensa/espressif/esp32s3/esp32s3_common.dtsi:385 */
			index = < 0x0 >;                      /* in zephyr/dts/xtensa/espressif/esp32s3/esp32s3_common.dtsi:386 */
			interrupts = < 0x35 0x0 0x0 >;        /* in zephyr/dts/xtensa/espressif/esp32s3/esp32s3_common.dtsi:387 */
			interrupt-parent = < &intc >;         /* in zephyr/dts/xtensa/espressif/esp32s3/esp32s3_common.dtsi:388 */
			status = "disabled";                  /* in zephyr/boards/espressif/esp32s3_devkitc/esp32s3_devkitc_procpu.dts:133 */

			/* node '/soc/counter@60020000/counter' defined in zephyr/dts/xtensa/espressif/esp32s3/esp32s3_common.dtsi:391 */
			counter {
				compatible = "espressif,esp32-counter"; /* in zephyr/dts/xtensa/espressif/esp32s3/esp32s3_common.dtsi:392 */
				status = "disabled";                    /* in zephyr/dts/xtensa/espressif/esp32s3/esp32s3_common.dtsi:393 */
			};
		};

		/* node '/soc/counter@60020024' defined in zephyr/dts/xtensa/espressif/esp32s3/esp32s3_common.dtsi:397 */
		timer3: counter@60020024 {
			compatible = "espressif,esp32-timer"; /* in zephyr/dts/xtensa/espressif/esp32s3/esp32s3_common.dtsi:398 */
			reg = < 0x60020024 0x1000 >;          /* in zephyr/dts/xtensa/espressif/esp32s3/esp32s3_common.dtsi:399 */
			clocks = < &clock 0x4 >;              /* in zephyr/dts/xtensa/espressif/esp32s3/esp32s3_common.dtsi:400 */
			group = < 0x1 >;                      /* in zephyr/dts/xtensa/espressif/esp32s3/esp32s3_common.dtsi:401 */
			index = < 0x1 >;                      /* in zephyr/dts/xtensa/espressif/esp32s3/esp32s3_common.dtsi:402 */
			interrupts = < 0x36 0x0 0x0 >;        /* in zephyr/dts/xtensa/espressif/esp32s3/esp32s3_common.dtsi:403 */
			interrupt-parent = < &intc >;         /* in zephyr/dts/xtensa/espressif/esp32s3/esp32s3_common.dtsi:404 */
			status = "disabled";                  /* in zephyr/boards/espressif/esp32s3_devkitc/esp32s3_devkitc_procpu.dts:137 */

			/* node '/soc/counter@60020024/counter' defined in zephyr/dts/xtensa/espressif/esp32s3/esp32s3_common.dtsi:406 */
			counter {
				compatible = "espressif,esp32-counter"; /* in zephyr/dts/xtensa/espressif/esp32s3/esp32s3_common.dtsi:407 */
				status = "disabled";                    /* in zephyr/dts/xtensa/espressif/esp32s3/esp32s3_common.dtsi:408 */
			};
		};

		/* node '/soc/watchdog@60020048' defined in zephyr/dts/xtensa/espressif/esp32s3/esp32s3_common.dtsi:412 */
		wdt1: watchdog@60020048 {
			compatible = "espressif,esp32-watchdog"; /* in zephyr/dts/xtensa/espressif/esp32s3/esp32s3_common.dtsi:413 */
			reg = < 0x60020048 0x20 >;               /* in zephyr/dts/xtensa/espressif/esp32s3/esp32s3_common.dtsi:414 */
			interrupts = < 0x37 0x0 0x0 >;           /* in zephyr/dts/xtensa/espressif/esp32s3/esp32s3_common.dtsi:415 */
			interrupt-parent = < &intc >;            /* in zephyr/dts/xtensa/espressif/esp32s3/esp32s3_common.dtsi:416 */
			clocks = < &clock 0x4 >;                 /* in zephyr/dts/xtensa/espressif/esp32s3/esp32s3_common.dtsi:417 */
			status = "disabled";                     /* in zephyr/dts/xtensa/espressif/esp32s3/esp32s3_common.dtsi:418 */
		};

		/* node '/soc/xt_wdt@60021004' defined in zephyr/dts/xtensa/espressif/esp32s3/esp32s3_common.dtsi:421 */
		xt_wdt: xt_wdt@60021004 {
			compatible = "espressif,esp32-xt-wdt"; /* in zephyr/dts/xtensa/espressif/esp32s3/esp32s3_common.dtsi:422 */
			reg = < 0x60021004 0x4 >;              /* in zephyr/dts/xtensa/espressif/esp32s3/esp32s3_common.dtsi:423 */
			clocks = < &clock 0xc >;               /* in zephyr/dts/xtensa/espressif/esp32s3/esp32s3_common.dtsi:424 */
			interrupts = < 0x27 0x0 0x0 >;         /* in zephyr/dts/xtensa/espressif/esp32s3/esp32s3_common.dtsi:425 */
			interrupt-parent = < &intc >;          /* in zephyr/dts/xtensa/espressif/esp32s3/esp32s3_common.dtsi:426 */
			status = "disabled";                   /* in zephyr/dts/xtensa/espressif/esp32s3/esp32s3_common.dtsi:427 */
		};

		/* node '/soc/spi@60024000' defined in zephyr/dts/xtensa/espressif/esp32s3/esp32s3_common.dtsi:430 */
		spi2: spi@60024000 {
			compatible = "espressif,esp32-spi"; /* in zephyr/dts/xtensa/espressif/esp32s3/esp32s3_common.dtsi:431 */
			reg = < 0x60024000 0x1000 >;        /* in zephyr/dts/xtensa/espressif/esp32s3/esp32s3_common.dtsi:432 */
			interrupts = < 0x15 0x0 0x0 >;      /* in zephyr/dts/xtensa/espressif/esp32s3/esp32s3_common.dtsi:433 */
			interrupt-parent = < &intc >;       /* in zephyr/dts/xtensa/espressif/esp32s3/esp32s3_common.dtsi:434 */
			clocks = < &clock 0x73 >;           /* in zephyr/dts/xtensa/espressif/esp32s3/esp32s3_common.dtsi:435 */
			dma-host = < 0x0 >;                 /* in zephyr/dts/xtensa/espressif/esp32s3/esp32s3_common.dtsi:436 */
			#address-cells = < 0x1 >;           /* in zephyr/boards/espressif/esp32s3_devkitc/esp32s3_devkitc_procpu.dts:104 */
			#size-cells = < 0x0 >;              /* in zephyr/boards/espressif/esp32s3_devkitc/esp32s3_devkitc_procpu.dts:105 */
			pinctrl-0 = < &spim2_default >;     /* in zephyr/boards/espressif/esp32s3_devkitc/esp32s3_devkitc_procpu.dts:106 */
			pinctrl-names = "default";          /* in zephyr/boards/espressif/esp32s3_devkitc/esp32s3_devkitc_procpu.dts:107 */
			status = "okay";                    /* in zephyr/boards/espressif/esp32s3_devkitc/esp32s3_devkitc_procpu.dts:108 */
		};

		/* node '/soc/spi@60025000' defined in zephyr/dts/xtensa/espressif/esp32s3/esp32s3_common.dtsi:440 */
		spi3: spi@60025000 {
			compatible = "espressif,esp32-spi"; /* in zephyr/dts/xtensa/espressif/esp32s3/esp32s3_common.dtsi:441 */
			reg = < 0x60025000 0x1000 >;        /* in zephyr/dts/xtensa/espressif/esp32s3/esp32s3_common.dtsi:442 */
			interrupts = < 0x16 0x0 0x0 >;      /* in zephyr/dts/xtensa/espressif/esp32s3/esp32s3_common.dtsi:443 */
			interrupt-parent = < &intc >;       /* in zephyr/dts/xtensa/espressif/esp32s3/esp32s3_common.dtsi:444 */
			clocks = < &clock 0x74 >;           /* in zephyr/dts/xtensa/espressif/esp32s3/esp32s3_common.dtsi:445 */
			dma-host = < 0x1 >;                 /* in zephyr/dts/xtensa/espressif/esp32s3/esp32s3_common.dtsi:446 */
			#address-cells = < 0x1 >;           /* in zephyr/boards/espressif/esp32s3_devkitc/esp32s3_devkitc_procpu.dts:112 */
			#size-cells = < 0x0 >;              /* in zephyr/boards/espressif/esp32s3_devkitc/esp32s3_devkitc_procpu.dts:113 */
			pinctrl-0 = < &spim3_default >;     /* in zephyr/boards/espressif/esp32s3_devkitc/esp32s3_devkitc_procpu.dts:114 */
			pinctrl-names = "default";          /* in zephyr/boards/espressif/esp32s3_devkitc/esp32s3_devkitc_procpu.dts:115 */
			status = "okay";                    /* in zephyr/boards/espressif/esp32s3_devkitc/esp32s3_devkitc_procpu.dts:116 */
		};

		/* node '/soc/i2c@60027000' defined in zephyr/dts/xtensa/espressif/esp32s3/esp32s3_common.dtsi:450 */
		i2c1: i2c@60027000 {
			compatible = "espressif,esp32-i2c"; /* in zephyr/dts/xtensa/espressif/esp32s3/esp32s3_common.dtsi:451 */
			reg = < 0x60027000 0x1000 >;        /* in zephyr/dts/xtensa/espressif/esp32s3/esp32s3_common.dtsi:452 */
			#address-cells = < 0x1 >;           /* in zephyr/dts/xtensa/espressif/esp32s3/esp32s3_common.dtsi:453 */
			#size-cells = < 0x0 >;              /* in zephyr/dts/xtensa/espressif/esp32s3/esp32s3_common.dtsi:454 */
			interrupts = < 0x2b 0x0 0x0 >;      /* in zephyr/dts/xtensa/espressif/esp32s3/esp32s3_common.dtsi:455 */
			interrupt-parent = < &intc >;       /* in zephyr/dts/xtensa/espressif/esp32s3/esp32s3_common.dtsi:456 */
			clocks = < &clock 0x68 >;           /* in zephyr/dts/xtensa/espressif/esp32s3/esp32s3_common.dtsi:457 */
			status = "disabled";                /* in zephyr/dts/xtensa/espressif/esp32s3/esp32s3_common.dtsi:458 */
			clock-frequency = < 0x186a0 >;      /* in zephyr/boards/espressif/esp32s3_devkitc/esp32s3_devkitc_procpu.dts:88 */
			pinctrl-0 = < &i2c1_default >;      /* in zephyr/boards/espressif/esp32s3_devkitc/esp32s3_devkitc_procpu.dts:89 */
			pinctrl-names = "default";          /* in zephyr/boards/espressif/esp32s3_devkitc/esp32s3_devkitc_procpu.dts:90 */
		};

		/* node '/soc/sdhc@60028000' defined in zephyr/dts/xtensa/espressif/esp32s3/esp32s3_common.dtsi:461 */
		sdhc: sdhc@60028000 {
			compatible = "espressif,esp32-sdhc"; /* in zephyr/dts/xtensa/espressif/esp32s3/esp32s3_common.dtsi:462 */
			reg = < 0x60028000 0x1000 >;         /* in zephyr/dts/xtensa/espressif/esp32s3/esp32s3_common.dtsi:463 */
			interrupts = < 0x1e 0x0 0x0 >;       /* in zephyr/dts/xtensa/espressif/esp32s3/esp32s3_common.dtsi:464 */
			interrupt-parent = < &intc >;        /* in zephyr/dts/xtensa/espressif/esp32s3/esp32s3_common.dtsi:465 */
			clocks = < &clock 0x75 >;            /* in zephyr/dts/xtensa/espressif/esp32s3/esp32s3_common.dtsi:466 */
			#address-cells = < 0x1 >;            /* in zephyr/dts/xtensa/espressif/esp32s3/esp32s3_common.dtsi:467 */
			#size-cells = < 0x0 >;               /* in zephyr/dts/xtensa/espressif/esp32s3/esp32s3_common.dtsi:468 */

			/* node '/soc/sdhc@60028000/sdhc@0' defined in zephyr/dts/xtensa/espressif/esp32s3/esp32s3_common.dtsi:470 */
			sdhc0: sdhc@0 {
				compatible = "espressif,esp32-sdhc-slot"; /* in zephyr/dts/xtensa/espressif/esp32s3/esp32s3_common.dtsi:471 */
				reg = < 0x0 >;                            /* in zephyr/dts/xtensa/espressif/esp32s3/esp32s3_common.dtsi:472 */
				status = "disabled";                      /* in zephyr/dts/xtensa/espressif/esp32s3/esp32s3_common.dtsi:473 */
			};

			/* node '/soc/sdhc@60028000/sdhc@1' defined in zephyr/dts/xtensa/espressif/esp32s3/esp32s3_common.dtsi:476 */
			sdhc1: sdhc@1 {
				compatible = "espressif,esp32-sdhc-slot"; /* in zephyr/dts/xtensa/espressif/esp32s3/esp32s3_common.dtsi:477 */
				reg = < 0x1 >;                            /* in zephyr/dts/xtensa/espressif/esp32s3/esp32s3_common.dtsi:478 */
				status = "disabled";                      /* in zephyr/dts/xtensa/espressif/esp32s3/esp32s3_common.dtsi:479 */
			};
		};

		/* node '/soc/can@6002b000' defined in zephyr/dts/xtensa/espressif/esp32s3/esp32s3_common.dtsi:483 */
		twai: can@6002b000 {
			compatible = "espressif,esp32-twai"; /* in zephyr/dts/xtensa/espressif/esp32s3/esp32s3_common.dtsi:484 */
			reg = < 0x6002b000 0x1000 >;         /* in zephyr/dts/xtensa/espressif/esp32s3/esp32s3_common.dtsi:485 */
			interrupts = < 0x25 0x0 0x0 >;       /* in zephyr/dts/xtensa/espressif/esp32s3/esp32s3_common.dtsi:486 */
			interrupt-parent = < &intc >;        /* in zephyr/dts/xtensa/espressif/esp32s3/esp32s3_common.dtsi:487 */
			clocks = < &clock 0x76 >;            /* in zephyr/dts/xtensa/espressif/esp32s3/esp32s3_common.dtsi:488 */
			status = "disabled";                 /* in zephyr/dts/xtensa/espressif/esp32s3/esp32s3_common.dtsi:489 */
			pinctrl-0 = < &twai_default >;       /* in zephyr/boards/espressif/esp32s3_devkitc/esp32s3_devkitc_procpu.dts:120 */
			pinctrl-names = "default";           /* in zephyr/boards/espressif/esp32s3_devkitc/esp32s3_devkitc_procpu.dts:121 */
		};

		/* node '/soc/mcpwm@6002c000' defined in zephyr/dts/xtensa/espressif/esp32s3/esp32s3_common.dtsi:492 */
		mcpwm1: mcpwm@6002c000 {
			compatible = "espressif,esp32-mcpwm"; /* in zephyr/dts/xtensa/espressif/esp32s3/esp32s3_common.dtsi:493 */
			reg = < 0x6002c000 0x1000 >;          /* in zephyr/dts/xtensa/espressif/esp32s3/esp32s3_common.dtsi:494 */
			interrupts = < 0x20 0x0 0x0 >;        /* in zephyr/dts/xtensa/espressif/esp32s3/esp32s3_common.dtsi:495 */
			interrupt-parent = < &intc >;         /* in zephyr/dts/xtensa/espressif/esp32s3/esp32s3_common.dtsi:496 */
			clocks = < &clock 0x6c >;             /* in zephyr/dts/xtensa/espressif/esp32s3/esp32s3_common.dtsi:497 */
			#pwm-cells = < 0x3 >;                 /* in zephyr/dts/xtensa/espressif/esp32s3/esp32s3_common.dtsi:498 */
			status = "disabled";                  /* in zephyr/dts/xtensa/espressif/esp32s3/esp32s3_common.dtsi:499 */
		};

		/* node '/soc/i2s@6002d000' defined in zephyr/dts/xtensa/espressif/esp32s3/esp32s3_common.dtsi:502 */
		i2s1: i2s@6002d000 {
			compatible = "espressif,esp32-i2s"; /* in zephyr/dts/xtensa/espressif/esp32s3/esp32s3_common.dtsi:503 */
			reg = < 0x6002d000 0x1000 >;        /* in zephyr/dts/xtensa/espressif/esp32s3/esp32s3_common.dtsi:504 */
			#address-cells = < 0x1 >;           /* in zephyr/dts/xtensa/espressif/esp32s3/esp32s3_common.dtsi:505 */
			#size-cells = < 0x0 >;              /* in zephyr/dts/xtensa/espressif/esp32s3/esp32s3_common.dtsi:506 */
			interrupts = < 0x1a 0x0 0x0 >;      /* in zephyr/dts/xtensa/espressif/esp32s3/esp32s3_common.dtsi:507 */
			interrupt-parent = < &intc >;       /* in zephyr/dts/xtensa/espressif/esp32s3/esp32s3_common.dtsi:508 */
			clocks = < &clock 0x6a >;           /* in zephyr/dts/xtensa/espressif/esp32s3/esp32s3_common.dtsi:509 */
			dmas = < &dma 0x4 >,
			       < &dma 0x5 >;                /* in zephyr/dts/xtensa/espressif/esp32s3/esp32s3_common.dtsi:510 */
			dma-names = "rx",
			            "tx";                   /* in zephyr/dts/xtensa/espressif/esp32s3/esp32s3_common.dtsi:511 */
			unit = < 0x1 >;                     /* in zephyr/dts/xtensa/espressif/esp32s3/esp32s3_common.dtsi:512 */
			status = "disabled";                /* in zephyr/dts/xtensa/espressif/esp32s3/esp32s3_common.dtsi:513 */
			pinctrl-0 = < &i2s1_default >;      /* in zephyr/boards/espressif/esp32s3_devkitc/esp32s3_devkitc_procpu.dts:99 */
			pinctrl-names = "default";          /* in zephyr/boards/espressif/esp32s3_devkitc/esp32s3_devkitc_procpu.dts:100 */
		};

		/* node '/soc/uart@6002e000' defined in zephyr/dts/xtensa/espressif/esp32s3/esp32s3_common.dtsi:516 */
		uart2: uart@6002e000 {
			compatible = "espressif,esp32-uart"; /* in zephyr/dts/xtensa/espressif/esp32s3/esp32s3_common.dtsi:517 */
			reg = < 0x6002e000 0x1000 >;         /* in zephyr/dts/xtensa/espressif/esp32s3/esp32s3_common.dtsi:518 */
			interrupts = < 0x1d 0x0 0x0 >;       /* in zephyr/dts/xtensa/espressif/esp32s3/esp32s3_common.dtsi:519 */
			interrupt-parent = < &intc >;        /* in zephyr/dts/xtensa/espressif/esp32s3/esp32s3_common.dtsi:520 */
			clocks = < &clock 0x1 >;             /* in zephyr/dts/xtensa/espressif/esp32s3/esp32s3_common.dtsi:521 */
			status = "disabled";                 /* in zephyr/dts/xtensa/espressif/esp32s3/esp32s3_common.dtsi:522 */
		};

		/* node '/soc/trng@6003507c' defined in zephyr/dts/xtensa/espressif/esp32s3/esp32s3_common.dtsi:525 */
		trng0: trng@6003507c {
			compatible = "espressif,esp32-trng"; /* in zephyr/dts/xtensa/espressif/esp32s3/esp32s3_common.dtsi:526 */
			reg = < 0x6003507c 0x4 >;            /* in zephyr/dts/xtensa/espressif/esp32s3/esp32s3_common.dtsi:527 */
			clocks = < &clock 0x6 >;             /* in zephyr/dts/xtensa/espressif/esp32s3/esp32s3_common.dtsi:528 */
			status = "okay";                     /* in zephyr/boards/espressif/esp32s3_devkitc/esp32s3_devkitc_procpu.dts:145 */
		};

		/* node '/soc/uart@60038000' defined in zephyr/dts/xtensa/espressif/esp32s3/esp32s3_common.dtsi:532 */
		usb_serial: uart@60038000 {
			compatible = "espressif,esp32-usb-serial"; /* in zephyr/dts/xtensa/espressif/esp32s3/esp32s3_common.dtsi:533 */
			reg = < 0x60038000 0x1000 >;               /* in zephyr/dts/xtensa/espressif/esp32s3/esp32s3_common.dtsi:534 */
			interrupts = < 0x60 0x0 0x0 >;             /* in zephyr/dts/xtensa/espressif/esp32s3/esp32s3_common.dtsi:535 */
			interrupt-parent = < &intc >;              /* in zephyr/dts/xtensa/espressif/esp32s3/esp32s3_common.dtsi:536 */
			clocks = < &clock 0x66 >;                  /* in zephyr/dts/xtensa/espressif/esp32s3/esp32s3_common.dtsi:537 */
			status = "disabled";                       /* in zephyr/boards/espressif/esp32s3_devkitc/esp32s3_devkitc_procpu.dts:51 */
		};

		/* node '/soc/aes@6003a000' defined in zephyr/dts/xtensa/espressif/esp32s3/esp32s3_common.dtsi:541 */
		aes: aes@6003a000 {
			compatible = "espressif,esp32-aes"; /* in zephyr/dts/xtensa/espressif/esp32s3/esp32s3_common.dtsi:542 */
			reg = < 0x6003a000 0x1000 >;        /* in zephyr/dts/xtensa/espressif/esp32s3/esp32s3_common.dtsi:543 */
			clocks = < &clock 0x79 >;           /* in zephyr/dts/xtensa/espressif/esp32s3/esp32s3_common.dtsi:544 */
			status = "okay";                    /* in zephyr/dts/xtensa/espressif/esp32s3/esp32s3_common.dtsi:545 */
		};

		/* node '/soc/sha@6003b000' defined in zephyr/dts/xtensa/espressif/esp32s3/esp32s3_common.dtsi:548 */
		sha: sha@6003b000 {
			compatible = "espressif,esp32-sha"; /* in zephyr/dts/xtensa/espressif/esp32s3/esp32s3_common.dtsi:549 */
			reg = < 0x6003b000 0x100 >;         /* in zephyr/dts/xtensa/espressif/esp32s3/esp32s3_common.dtsi:550 */
			clocks = < &clock 0x7a >;           /* in zephyr/dts/xtensa/espressif/esp32s3/esp32s3_common.dtsi:551 */
			status = "okay";                    /* in zephyr/dts/xtensa/espressif/esp32s3/esp32s3_common.dtsi:552 */
		};

		/* node '/soc/dma@6003f000' defined in zephyr/dts/xtensa/espressif/esp32s3/esp32s3_common.dtsi:555 */
		dma: dma@6003f000 {
			compatible = "espressif,esp32-gdma"; /* in zephyr/dts/xtensa/espressif/esp32s3/esp32s3_common.dtsi:556 */
			reg = < 0x6003f000 0x1000 >;         /* in zephyr/dts/xtensa/espressif/esp32s3/esp32s3_common.dtsi:557 */
			#dma-cells = < 0x1 >;                /* in zephyr/dts/xtensa/espressif/esp32s3/esp32s3_common.dtsi:558 */
			interrupts = < 0x42 0x0 0x100 >,
			             < 0x47 0x0 0x100 >,
			             < 0x43 0x0 0x100 >,
			             < 0x48 0x0 0x100 >,
			             < 0x44 0x0 0x100 >,
			             < 0x49 0x0 0x100 >,
			             < 0x45 0x0 0x100 >,
			             < 0x4a 0x0 0x100 >,
			             < 0x46 0x0 0x100 >,
			             < 0x4b 0x0 0x100 >;     /* in zephyr/dts/xtensa/espressif/esp32s3/esp32s3_common.dtsi:559 */
			interrupt-parent = < &intc >;        /* in zephyr/dts/xtensa/espressif/esp32s3/esp32s3_common.dtsi:579 */
			clocks = < &clock 0x7e >;            /* in zephyr/dts/xtensa/espressif/esp32s3/esp32s3_common.dtsi:580 */
			dma-channels = < 0xa >;              /* in zephyr/dts/xtensa/espressif/esp32s3/esp32s3_common.dtsi:581 */
			dma-buf-addr-alignment = < 0x4 >;    /* in zephyr/dts/xtensa/espressif/esp32s3/esp32s3_common.dtsi:582 */
			status = "disabled";                 /* in zephyr/dts/xtensa/espressif/esp32s3/esp32s3_common.dtsi:583 */
			phandle = < 0x7 >;                   /* in zephyr/dts/xtensa/espressif/esp32s3/esp32s3_common.dtsi:277 */
		};

		/* node '/soc/adc@60040000' defined in zephyr/dts/xtensa/espressif/esp32s3/esp32s3_common.dtsi:586 */
		adc0: adc@60040000 {
			compatible = "espressif,esp32-adc"; /* in zephyr/dts/xtensa/espressif/esp32s3/esp32s3_common.dtsi:587 */
			reg = < 0x60040000 0x4 >;           /* in zephyr/dts/xtensa/espressif/esp32s3/esp32s3_common.dtsi:588 */
			clocks = < &clock 0x80 >;           /* in zephyr/dts/xtensa/espressif/esp32s3/esp32s3_common.dtsi:589 */
			unit = < 0x1 >;                     /* in zephyr/dts/xtensa/espressif/esp32s3/esp32s3_common.dtsi:590 */
			channel-count = < 0xa >;            /* in zephyr/dts/xtensa/espressif/esp32s3/esp32s3_common.dtsi:591 */
			#io-channel-cells = < 0x1 >;        /* in zephyr/dts/xtensa/espressif/esp32s3/esp32s3_common.dtsi:592 */
			status = "disabled";                /* in zephyr/dts/xtensa/espressif/esp32s3/esp32s3_common.dtsi:593 */
		};

		/* node '/soc/adc@60040004' defined in zephyr/dts/xtensa/espressif/esp32s3/esp32s3_common.dtsi:596 */
		adc1: adc@60040004 {
			compatible = "espressif,esp32-adc"; /* in zephyr/dts/xtensa/espressif/esp32s3/esp32s3_common.dtsi:597 */
			reg = < 0x60040004 0x4 >;           /* in zephyr/dts/xtensa/espressif/esp32s3/esp32s3_common.dtsi:598 */
			clocks = < &clock 0x80 >;           /* in zephyr/dts/xtensa/espressif/esp32s3/esp32s3_common.dtsi:599 */
			unit = < 0x2 >;                     /* in zephyr/dts/xtensa/espressif/esp32s3/esp32s3_common.dtsi:600 */
			channel-count = < 0xa >;            /* in zephyr/dts/xtensa/espressif/esp32s3/esp32s3_common.dtsi:601 */
			#io-channel-cells = < 0x1 >;        /* in zephyr/dts/xtensa/espressif/esp32s3/esp32s3_common.dtsi:602 */
			status = "disabled";                /* in zephyr/dts/xtensa/espressif/esp32s3/esp32s3_common.dtsi:603 */
		};

		/* node '/soc/lcd_cam@60041000' defined in zephyr/dts/xtensa/espressif/esp32s3/esp32s3_common.dtsi:606 */
		lcd_cam: lcd_cam@60041000 {
			compatible = "espressif,esp32-lcd-cam"; /* in zephyr/dts/xtensa/espressif/esp32s3/esp32s3_common.dtsi:607 */
			reg = < 0x60041000 0x1000 >;            /* in zephyr/dts/xtensa/espressif/esp32s3/esp32s3_common.dtsi:608 */
			clocks = < &clock 0x2 >;                /* in zephyr/dts/xtensa/espressif/esp32s3/esp32s3_common.dtsi:609 */
			interrupts = < 0x18 0x0 0x0 >;          /* in zephyr/dts/xtensa/espressif/esp32s3/esp32s3_common.dtsi:610 */
			interrupt-parent = < &intc >;           /* in zephyr/dts/xtensa/espressif/esp32s3/esp32s3_common.dtsi:611 */
			dmas = < &dma 0x6 >,
			       < &dma 0x7 >;                    /* in zephyr/dts/xtensa/espressif/esp32s3/esp32s3_common.dtsi:612 */
			dma-names = "rx",
			            "tx";                       /* in zephyr/dts/xtensa/espressif/esp32s3/esp32s3_common.dtsi:613 */

			/* node '/soc/lcd_cam@60041000/lcd_cam_dvp' defined in zephyr/dts/xtensa/espressif/esp32s3/esp32s3_common.dtsi:615 */
			lcd_cam_dvp: lcd_cam_dvp {
				compatible = "espressif,esp32-lcd-cam-dvp"; /* in zephyr/dts/xtensa/espressif/esp32s3/esp32s3_common.dtsi:616 */
				status = "disabled";                        /* in zephyr/dts/xtensa/espressif/esp32s3/esp32s3_common.dtsi:617 */
			};

			/* node '/soc/lcd_cam@60041000/lcd_cam_disp' defined in zephyr/dts/xtensa/espressif/esp32s3/esp32s3_common.dtsi:620 */
			lcd_cam_disp: lcd_cam_disp {
				compatible = "espressif,esp32-lcd-cam-mipi-dbi"; /* in zephyr/dts/xtensa/espressif/esp32s3/esp32s3_common.dtsi:621 */
				#address-cells = < 0x1 >;                        /* in zephyr/dts/xtensa/espressif/esp32s3/esp32s3_common.dtsi:622 */
				#size-cells = < 0x0 >;                           /* in zephyr/dts/xtensa/espressif/esp32s3/esp32s3_common.dtsi:623 */
				status = "disabled";                             /* in zephyr/dts/xtensa/espressif/esp32s3/esp32s3_common.dtsi:624 */
			};
		};

		/* node '/soc/usb_otg@60080000' defined in zephyr/dts/xtensa/espressif/esp32s3/esp32s3_common.dtsi:628 */
		usb_otg: zephyr_udc0: zephyr_uhc0: usb_otg@60080000 {
			compatible = "espressif,esp32-usb-otg-fs",
			             "snps,dwc2";                  /* in zephyr/dts/xtensa/espressif/esp32s3/esp32s3_common.dtsi:629 */
			reg = < 0x60080000 0x40000 >;              /* in zephyr/dts/xtensa/espressif/esp32s3/esp32s3_common.dtsi:630 */
			interrupts = < 0x26 0x0 0x0 >;             /* in zephyr/dts/xtensa/espressif/esp32s3/esp32s3_common.dtsi:631 */
			interrupt-parent = < &intc >;              /* in zephyr/dts/xtensa/espressif/esp32s3/esp32s3_common.dtsi:632 */
			clocks = < &clock 0x66 >;                  /* in zephyr/dts/xtensa/espressif/esp32s3/esp32s3_common.dtsi:633 */
			num-out-eps = < 0x6 >;                     /* in zephyr/dts/xtensa/espressif/esp32s3/esp32s3_common.dtsi:634 */
			num-in-eps = < 0x6 >;                      /* in zephyr/dts/xtensa/espressif/esp32s3/esp32s3_common.dtsi:635 */
			ghwcfg1 = < 0x0 >;                         /* in zephyr/dts/xtensa/espressif/esp32s3/esp32s3_common.dtsi:636 */
			ghwcfg2 = < 0x224dd930 >;                  /* in zephyr/dts/xtensa/espressif/esp32s3/esp32s3_common.dtsi:637 */
			ghwcfg4 = < 0xd3f0a030 >;                  /* in zephyr/dts/xtensa/espressif/esp32s3/esp32s3_common.dtsi:638 */
			g-rx-fifo-size = < 0x40 >;                 /* in zephyr/dts/xtensa/espressif/esp32s3/esp32s3_common.dtsi:639 */
			g-np-tx-fifo-size = < 0x10 >;              /* in zephyr/dts/xtensa/espressif/esp32s3/esp32s3_common.dtsi:640 */
			g-tx-fifo-size = < 0x20 0x20 0x20 0x18 >;  /* in zephyr/dts/xtensa/espressif/esp32s3/esp32s3_common.dtsi:641 */
			phy-dp-pin = < 0x14 >;                     /* in zephyr/dts/xtensa/espressif/esp32s3/esp32s3_common.dtsi:642 */
			phy-dm-pin = < 0x13 >;                     /* in zephyr/dts/xtensa/espressif/esp32s3/esp32s3_common.dtsi:643 */
			status = "okay";                           /* in zephyr/boards/espressif/esp32s3_devkitc/esp32s3_devkitc_procpu.dts:161 */
		};

		/* node '/soc/interrupt-controller@600c2000' defined in zephyr/dts/xtensa/espressif/esp32s3/esp32s3_common.dtsi:647 */
		intc: interrupt-controller@600c2000 {
			compatible = "espressif,esp32-intc"; /* in zephyr/dts/xtensa/espressif/esp32s3/esp32s3_common.dtsi:648 */
			reg = < 0x600c2000 0x1000 >;         /* in zephyr/dts/xtensa/espressif/esp32s3/esp32s3_common.dtsi:649 */
			#interrupt-cells = < 0x3 >;          /* in zephyr/dts/xtensa/espressif/esp32s3/esp32s3_common.dtsi:650 */
			#address-cells = < 0x0 >;            /* in zephyr/dts/xtensa/espressif/esp32s3/esp32s3_common.dtsi:651 */
			interrupt-controller;                /* in zephyr/dts/xtensa/espressif/esp32s3/esp32s3_common.dtsi:652 */
			status = "okay";                     /* in zephyr/dts/xtensa/espressif/esp32s3/esp32s3_common.dtsi:653 */
			phandle = < 0x3 >;                   /* in zephyr/dts/xtensa/espressif/esp32s3/esp32s3_common.dtsi:119 */
		};

		/* node '/soc/memory@600fe000' defined in zephyr/dts/xtensa/espressif/esp32s3/esp32s3_common.dtsi:656 */
		rtc_fast_ram: memory@600fe000 {
			compatible = "zephyr,memory-region",
			             "mmio-sram";              /* in zephyr/dts/xtensa/espressif/esp32s3/esp32s3_common.dtsi:657 */
			reg = < 0x600fe000 0x2000 >;           /* in zephyr/dts/xtensa/espressif/esp32s3/esp32s3_common.dtsi:658 */
			zephyr,memory-region = "RTC_FAST_RAM"; /* in zephyr/dts/xtensa/espressif/esp32s3/esp32s3_common.dtsi:659 */
		};
	};

	/* node '/cpus' defined in zephyr/dts/xtensa/espressif/esp32s3/esp32s3_common.dtsi:28 */
	cpus {
		#address-cells = < 0x1 >; /* in zephyr/dts/xtensa/espressif/esp32s3/esp32s3_common.dtsi:29 */
		#size-cells = < 0x0 >;    /* in zephyr/dts/xtensa/espressif/esp32s3/esp32s3_common.dtsi:30 */

		/* node '/cpus/cpu@0' defined in zephyr/dts/xtensa/espressif/esp32s3/esp32s3_common.dtsi:32 */
		cpu0: cpu@0 {
			compatible = "espressif,xtensa-lx7";             /* in zephyr/dts/xtensa/espressif/esp32s3/esp32s3_common.dtsi:33 */
			reg = < 0x0 >;                                   /* in zephyr/dts/xtensa/espressif/esp32s3/esp32s3_common.dtsi:34 */
			device_type = "cpu";                             /* in zephyr/dts/xtensa/espressif/esp32s3/esp32s3_common.dtsi:35 */
			cpu-power-states = < &light_sleep &deep_sleep >; /* in zephyr/dts/xtensa/espressif/esp32s3/esp32s3_common.dtsi:36 */
			clock-source = < 0x1 >;                          /* in zephyr/dts/xtensa/espressif/esp32s3/esp32s3_common.dtsi:37 */
			clock-frequency = < 0xe4e1c00 >;                 /* in zephyr/dts/xtensa/espressif/esp32s3/esp32s3_common.dtsi:38 */
			xtal-freq = < 0x2625a00 >;                       /* in zephyr/dts/xtensa/espressif/esp32s3/esp32s3_common.dtsi:39 */
			d-cache-line-size = < 0x10 >;                    /* in zephyr/dts/xtensa/espressif/esp32s3/esp32s3_common.dtsi:40 */
		};

		/* node '/cpus/power-states' defined in zephyr/dts/xtensa/espressif/esp32s3/esp32s3_common.dtsi:43 */
		power-states {

			/* node '/cpus/power-states/light_sleep' defined in zephyr/dts/xtensa/espressif/esp32s3/esp32s3_common.dtsi:44 */
			light_sleep: light_sleep {
				compatible = "zephyr,power-state"; /* in zephyr/dts/xtensa/espressif/esp32s3/esp32s3_common.dtsi:45 */
				power-state-name = "standby";      /* in zephyr/dts/xtensa/espressif/esp32s3/esp32s3_common.dtsi:46 */
				min-residency-us = < 0x3e8 >;      /* in zephyr/dts/xtensa/espressif/esp32s3/esp32s3_common.dtsi:47 */
				exit-latency-us = < 0x0 >;         /* in zephyr/dts/xtensa/espressif/esp32s3/esp32s3_common.dtsi:48 */
				phandle = < 0x10 >;                /* in zephyr/dts/xtensa/espressif/esp32s3/esp32s3_common.dtsi:36 */
			};

			/* node '/cpus/power-states/deep_sleep' defined in zephyr/dts/xtensa/espressif/esp32s3/esp32s3_common.dtsi:51 */
			deep_sleep: deep_sleep {
				compatible = "zephyr,power-state"; /* in zephyr/dts/xtensa/espressif/esp32s3/esp32s3_common.dtsi:55 */
				power-state-name = "soft-off";     /* in zephyr/dts/xtensa/espressif/esp32s3/esp32s3_common.dtsi:56 */
				status = "disabled";               /* in zephyr/dts/xtensa/espressif/esp32s3/esp32s3_common.dtsi:57 */
				phandle = < 0x11 >;                /* in zephyr/dts/xtensa/espressif/esp32s3/esp32s3_common.dtsi:36 */
			};
		};

		/* node '/cpus/cpu@1' defined in zephyr/dts/xtensa/espressif/esp32s3/esp32s3_common.dtsi:61 */
		cpu1: cpu@1 {
			compatible = "espressif,xtensa-lx7"; /* in zephyr/dts/xtensa/espressif/esp32s3/esp32s3_common.dtsi:62 */
			reg = < 0x1 >;                       /* in zephyr/dts/xtensa/espressif/esp32s3/esp32s3_common.dtsi:63 */
			device_type = "cpu";                 /* in zephyr/dts/xtensa/espressif/esp32s3/esp32s3_common.dtsi:64 */
			clock-source = < 0x1 >;              /* in zephyr/dts/xtensa/espressif/esp32s3/esp32s3_common.dtsi:65 */
			clock-frequency = < 0xe4e1c00 >;     /* in zephyr/dts/xtensa/espressif/esp32s3/esp32s3_common.dtsi:66 */
			xtal-freq = < 0x2625a00 >;           /* in zephyr/dts/xtensa/espressif/esp32s3/esp32s3_common.dtsi:67 */
			d-cache-line-size = < 0x10 >;        /* in zephyr/dts/xtensa/espressif/esp32s3/esp32s3_common.dtsi:68 */
		};
	};

	/* node '/wifi' defined in zephyr/dts/xtensa/espressif/esp32s3/esp32s3_common.dtsi:72 */
	wifi: wifi {
		compatible = "espressif,esp32-wifi"; /* in zephyr/dts/xtensa/espressif/esp32s3/esp32s3_common.dtsi:73 */
		status = "okay";                     /* in zephyr/boards/espressif/esp32s3_devkitc/esp32s3_devkitc_procpu.dts:153 */
	};

	/* node '/esp32_bt_hci' defined in zephyr/dts/xtensa/espressif/esp32s3/esp32s3_common.dtsi:77 */
	esp32_bt_hci: esp32_bt_hci {
		compatible = "espressif,esp32-bt-hci"; /* in zephyr/dts/xtensa/espressif/esp32s3/esp32s3_common.dtsi:78 */
		bt-hci-vs-ext;                         /* in zephyr/dts/xtensa/espressif/esp32s3/esp32s3_common.dtsi:79 */
		status = "okay";                       /* in zephyr/boards/espressif/esp32s3_devkitc/esp32s3_devkitc_procpu.dts:149 */
	};

	/* node '/pin-controller' defined in zephyr/dts/xtensa/espressif/esp32s3/esp32s3_common.dtsi:83 */
	pinctrl: pin-controller {
		compatible = "espressif,esp32-pinctrl"; /* in zephyr/dts/xtensa/espressif/esp32s3/esp32s3_common.dtsi:84 */
		status = "okay";                        /* in zephyr/dts/xtensa/espressif/esp32s3/esp32s3_common.dtsi:85 */

		/* node '/pin-controller/uart0_default' defined in zephyr/boards/espressif/esp32s3_devkitc/esp32s3_devkitc-pinctrl.dtsi:10 */
		uart0_default: uart0_default {
			phandle = < 0x6 >; /* in zephyr/boards/espressif/esp32s3_devkitc/esp32s3_devkitc_procpu.dts:56 */

			/* node '/pin-controller/uart0_default/group1' defined in zephyr/boards/espressif/esp32s3_devkitc/esp32s3_devkitc-pinctrl.dtsi:11 */
			group1 {
				pinmux = < 0x67feb >; /* in zephyr/boards/espressif/esp32s3_devkitc/esp32s3_devkitc-pinctrl.dtsi:12 */
				output-high;          /* in zephyr/boards/espressif/esp32s3_devkitc/esp32s3_devkitc-pinctrl.dtsi:13 */
			};

			/* node '/pin-controller/uart0_default/group2' defined in zephyr/boards/espressif/esp32s3_devkitc/esp32s3_devkitc-pinctrl.dtsi:16 */
			group2 {
				pinmux = < 0xff832c >; /* in zephyr/boards/espressif/esp32s3_devkitc/esp32s3_devkitc-pinctrl.dtsi:17 */
				bias-pull-up;          /* in zephyr/boards/espressif/esp32s3_devkitc/esp32s3_devkitc-pinctrl.dtsi:18 */
			};
		};

		/* node '/pin-controller/uart1_default' defined in zephyr/boards/espressif/esp32s3_devkitc/esp32s3_devkitc-pinctrl.dtsi:22 */
		uart1_default: uart1_default {

			/* node '/pin-controller/uart1_default/group1' defined in zephyr/boards/espressif/esp32s3_devkitc/esp32s3_devkitc-pinctrl.dtsi:23 */
			group1 {
				pinmux = < 0x7ffd1 >; /* in zephyr/boards/espressif/esp32s3_devkitc/esp32s3_devkitc-pinctrl.dtsi:24 */
				output-high;          /* in zephyr/boards/espressif/esp32s3_devkitc/esp32s3_devkitc-pinctrl.dtsi:25 */
			};

			/* node '/pin-controller/uart1_default/group2' defined in zephyr/boards/espressif/esp32s3_devkitc/esp32s3_devkitc-pinctrl.dtsi:28 */
			group2 {
				pinmux = < 0xff83d2 >; /* in zephyr/boards/espressif/esp32s3_devkitc/esp32s3_devkitc-pinctrl.dtsi:29 */
				bias-pull-up;          /* in zephyr/boards/espressif/esp32s3_devkitc/esp32s3_devkitc-pinctrl.dtsi:30 */
			};
		};

		/* node '/pin-controller/i2c0_default' defined in zephyr/boards/espressif/esp32s3_devkitc/esp32s3_devkitc-pinctrl.dtsi:34 */
		i2c0_default: i2c0_default {
			phandle = < 0x9 >; /* in zephyr/boards/espressif/esp32s3_devkitc/esp32s3_devkitc_procpu.dts:83 */

			/* node '/pin-controller/i2c0_default/group1' defined in zephyr/boards/espressif/esp32s3_devkitc/esp32s3_devkitc-pinctrl.dtsi:35 */
			group1 {
				pinmux = < 0x2d1681 >,
				         < 0x2c9642 >; /* in zephyr/boards/espressif/esp32s3_devkitc/esp32s3_devkitc-pinctrl.dtsi:36 */
				bias-pull-up;          /* in zephyr/boards/espressif/esp32s3_devkitc/esp32s3_devkitc-pinctrl.dtsi:38 */
				drive-open-drain;      /* in zephyr/boards/espressif/esp32s3_devkitc/esp32s3_devkitc-pinctrl.dtsi:39 */
				output-high;           /* in zephyr/boards/espressif/esp32s3_devkitc/esp32s3_devkitc-pinctrl.dtsi:40 */
			};
		};

		/* node '/pin-controller/i2c1_default' defined in zephyr/boards/espressif/esp32s3_devkitc/esp32s3_devkitc-pinctrl.dtsi:44 */
		i2c1_default: i2c1_default {
			phandle = < 0xd >; /* in zephyr/boards/espressif/esp32s3_devkitc/esp32s3_devkitc_procpu.dts:89 */

			/* node '/pin-controller/i2c1_default/group1' defined in zephyr/boards/espressif/esp32s3_devkitc/esp32s3_devkitc-pinctrl.dtsi:45 */
			group1 {
				pinmux = < 0x2e1704 >,
				         < 0x2d96c5 >; /* in zephyr/boards/espressif/esp32s3_devkitc/esp32s3_devkitc-pinctrl.dtsi:46 */
				bias-pull-up;          /* in zephyr/boards/espressif/esp32s3_devkitc/esp32s3_devkitc-pinctrl.dtsi:48 */
				drive-open-drain;      /* in zephyr/boards/espressif/esp32s3_devkitc/esp32s3_devkitc-pinctrl.dtsi:49 */
				output-high;           /* in zephyr/boards/espressif/esp32s3_devkitc/esp32s3_devkitc-pinctrl.dtsi:50 */
			};
		};

		/* node '/pin-controller/i2s0_default' defined in zephyr/boards/espressif/esp32s3_devkitc/esp32s3_devkitc-pinctrl.dtsi:54 */
		i2s0_default: i2s0_default {
			phandle = < 0x8 >; /* in zephyr/boards/espressif/esp32s3_devkitc/esp32s3_devkitc_procpu.dts:94 */

			/* node '/pin-controller/i2s0_default/group1' defined in zephyr/boards/espressif/esp32s3_devkitc/esp32s3_devkitc-pinctrl.dtsi:55 */
			group1 {
				pinmux = < 0xbffea >,
				         < 0xc0624 >,
				         < 0xb05a5 >,
				         < 0xcffe6 >,
				         < 0xff8669 >; /* in zephyr/boards/espressif/esp32s3_devkitc/esp32s3_devkitc-pinctrl.dtsi:56 */
			};
		};

		/* node '/pin-controller/i2s1_default' defined in zephyr/boards/espressif/esp32s3_devkitc/esp32s3_devkitc-pinctrl.dtsi:64 */
		i2s1_default: i2s1_default {
			phandle = < 0xf >; /* in zephyr/boards/espressif/esp32s3_devkitc/esp32s3_devkitc_procpu.dts:99 */

			/* node '/pin-controller/i2s1_default/group1' defined in zephyr/boards/espressif/esp32s3_devkitc/esp32s3_devkitc-pinctrl.dtsi:65 */
			group1 {
				pinmux = < 0xafff0 >,
				         < 0xe8744 >,
				         < 0xe0705 >,
				         < 0xf7fc6 >,
				         < 0xff878c >; /* in zephyr/boards/espressif/esp32s3_devkitc/esp32s3_devkitc-pinctrl.dtsi:66 */
			};
		};

		/* node '/pin-controller/spim2_default' defined in zephyr/boards/espressif/esp32s3_devkitc/esp32s3_devkitc-pinctrl.dtsi:74 */
		spim2_default: spim2_default {
			phandle = < 0xb >; /* in zephyr/boards/espressif/esp32s3_devkitc/esp32s3_devkitc_procpu.dts:106 */

			/* node '/pin-controller/spim2_default/group1' defined in zephyr/boards/espressif/esp32s3_devkitc/esp32s3_devkitc-pinctrl.dtsi:75 */
			group1 {
				pinmux = < 0xff998d >,
				         < 0x32ffcc >,
				         < 0x377fca >; /* in zephyr/boards/espressif/esp32s3_devkitc/esp32s3_devkitc-pinctrl.dtsi:76 */
			};

			/* node '/pin-controller/spim2_default/group2' defined in zephyr/boards/espressif/esp32s3_devkitc/esp32s3_devkitc-pinctrl.dtsi:81 */
			group2 {
				pinmux = < 0x33ffcb >; /* in zephyr/boards/espressif/esp32s3_devkitc/esp32s3_devkitc-pinctrl.dtsi:82 */
				output-low;            /* in zephyr/boards/espressif/esp32s3_devkitc/esp32s3_devkitc-pinctrl.dtsi:83 */
			};
		};

		/* node '/pin-controller/spim3_default' defined in zephyr/boards/espressif/esp32s3_devkitc/esp32s3_devkitc-pinctrl.dtsi:88 */
		spim3_default: spim3_default {
			phandle = < 0xc >; /* in zephyr/boards/espressif/esp32s3_devkitc/esp32s3_devkitc_procpu.dts:114 */

			/* node '/pin-controller/spim3_default/group1' defined in zephyr/boards/espressif/esp32s3_devkitc/esp32s3_devkitc-pinctrl.dtsi:89 */
			group1 {
				pinmux = < 0xff90e8 >,
				         < 0x217fd5 >,
				         < 0x23ffce >; /* in zephyr/boards/espressif/esp32s3_devkitc/esp32s3_devkitc-pinctrl.dtsi:90 */
			};

			/* node '/pin-controller/spim3_default/group2' defined in zephyr/boards/espressif/esp32s3_devkitc/esp32s3_devkitc-pinctrl.dtsi:95 */
			group2 {
				pinmux = < 0x227fe9 >; /* in zephyr/boards/espressif/esp32s3_devkitc/esp32s3_devkitc-pinctrl.dtsi:96 */
				output-low;            /* in zephyr/boards/espressif/esp32s3_devkitc/esp32s3_devkitc-pinctrl.dtsi:97 */
			};
		};

		/* node '/pin-controller/twai_default' defined in zephyr/boards/espressif/esp32s3_devkitc/esp32s3_devkitc-pinctrl.dtsi:101 */
		twai_default: twai_default {
			phandle = < 0xe >; /* in zephyr/boards/espressif/esp32s3_devkitc/esp32s3_devkitc_procpu.dts:120 */

			/* node '/pin-controller/twai_default/group1' defined in zephyr/boards/espressif/esp32s3_devkitc/esp32s3_devkitc-pinctrl.dtsi:102 */
			group1 {
				pinmux = < 0x3a7fc5 >,
				         < 0xff9d06 >; /* in zephyr/boards/espressif/esp32s3_devkitc/esp32s3_devkitc-pinctrl.dtsi:103 */
			};
		};

		/* node '/pin-controller/rmt_default' defined in zephyr/boards/espressif/esp32s3_devkitc/esp32s3_devkitc-pinctrl.dtsi:108 */
		rmt_default: rmt_default {

			/* node '/pin-controller/rmt_default/group1' defined in zephyr/boards/espressif/esp32s3_devkitc/esp32s3_devkitc-pinctrl.dtsi:109 */
			group1 {
				pinmux = < 0x2a7fc8 >; /* in zephyr/boards/espressif/esp32s3_devkitc/esp32s3_devkitc-pinctrl.dtsi:110 */
			};

			/* node '/pin-controller/rmt_default/group2' defined in zephyr/boards/espressif/esp32s3_devkitc/esp32s3_devkitc-pinctrl.dtsi:113 */
			group2 {
				pinmux = < 0xff9509 >; /* in zephyr/boards/espressif/esp32s3_devkitc/esp32s3_devkitc-pinctrl.dtsi:114 */
			};
		};

		/* node '/pin-controller/rmt_status_led' defined in ../introduction-to-rtos/task-scheduling/esp32s3_devkitc_procpu.overlay:16 */
		rmt_status_led: rmt_status_led {
			phandle = < 0xa >; /* in ../introduction-to-rtos/task-scheduling/esp32s3_devkitc_procpu.overlay:24 */

			/* node '/pin-controller/rmt_status_led/group1' defined in ../introduction-to-rtos/task-scheduling/esp32s3_devkitc_procpu.overlay:17 */
			group1 {
				pinmux = < 0x28fff0 >; /* in ../introduction-to-rtos/task-scheduling/esp32s3_devkitc_procpu.overlay:18 */
			};
		};
	};

	/* node '/clock' defined in zephyr/dts/xtensa/espressif/esp32s3/esp32s3_common.dtsi:88 */
	clock: clock {
		compatible = "espressif,esp32-clock"; /* in zephyr/dts/xtensa/espressif/esp32s3/esp32s3_common.dtsi:89 */
		fast-clk-src = < 0x1 >;               /* in zephyr/dts/xtensa/espressif/esp32s3/esp32s3_common.dtsi:90 */
		slow-clk-src = < 0x0 >;               /* in zephyr/dts/xtensa/espressif/esp32s3/esp32s3_common.dtsi:91 */
		#clock-cells = < 0x1 >;               /* in zephyr/dts/xtensa/espressif/esp32s3/esp32s3_common.dtsi:92 */
		status = "okay";                      /* in zephyr/dts/xtensa/espressif/esp32s3/esp32s3_common.dtsi:93 */
		phandle = < 0x5 >;                    /* in zephyr/dts/xtensa/espressif/esp32s3/esp32s3_common.dtsi:224 */
	};

	/* node '/buttons' defined in zephyr/boards/espressif/esp32s3_devkitc/esp32s3_devkitc_procpu.dts:34 */
	buttons {
		compatible = "gpio-keys"; /* in zephyr/boards/espressif/esp32s3_devkitc/esp32s3_devkitc_procpu.dts:35 */

		/* node '/buttons/button_0' defined in zephyr/boards/espressif/esp32s3_devkitc/esp32s3_devkitc_procpu.dts:37 */
		button0: button_0 {
			gpios = < &gpio0 0x0 0x11 >; /* in zephyr/boards/espressif/esp32s3_devkitc/esp32s3_devkitc_procpu.dts:38 */
			label = "BOOT Button";       /* in zephyr/boards/espressif/esp32s3_devkitc/esp32s3_devkitc_procpu.dts:39 */
			zephyr,code = < 0xb >;       /* in zephyr/boards/espressif/esp32s3_devkitc/esp32s3_devkitc_procpu.dts:40 */
		};
	};

	/* node '/ws2812' defined in ../introduction-to-rtos/task-scheduling/esp32s3_devkitc_procpu.overlay:4 */
	status_led: ws2812 {
		compatible = "worldsemi,ws2812-pulse-io"; /* in ../introduction-to-rtos/task-scheduling/esp32s3_devkitc_procpu.overlay:5 */
		pulse-ios = < &rmt 0x0 >;                 /* in ../introduction-to-rtos/task-scheduling/esp32s3_devkitc_procpu.overlay:6 */
		chain-length = < 0x1 >;                   /* in ../introduction-to-rtos/task-scheduling/esp32s3_devkitc_procpu.overlay:7 */
		color-mapping = < 0x2 0x1 0x3 >;          /* in ../introduction-to-rtos/task-scheduling/esp32s3_devkitc_procpu.overlay:8 */
		reset-delay = < 0x12c >;                  /* in ../introduction-to-rtos/task-scheduling/esp32s3_devkitc_procpu.overlay:11 */
	};
};
